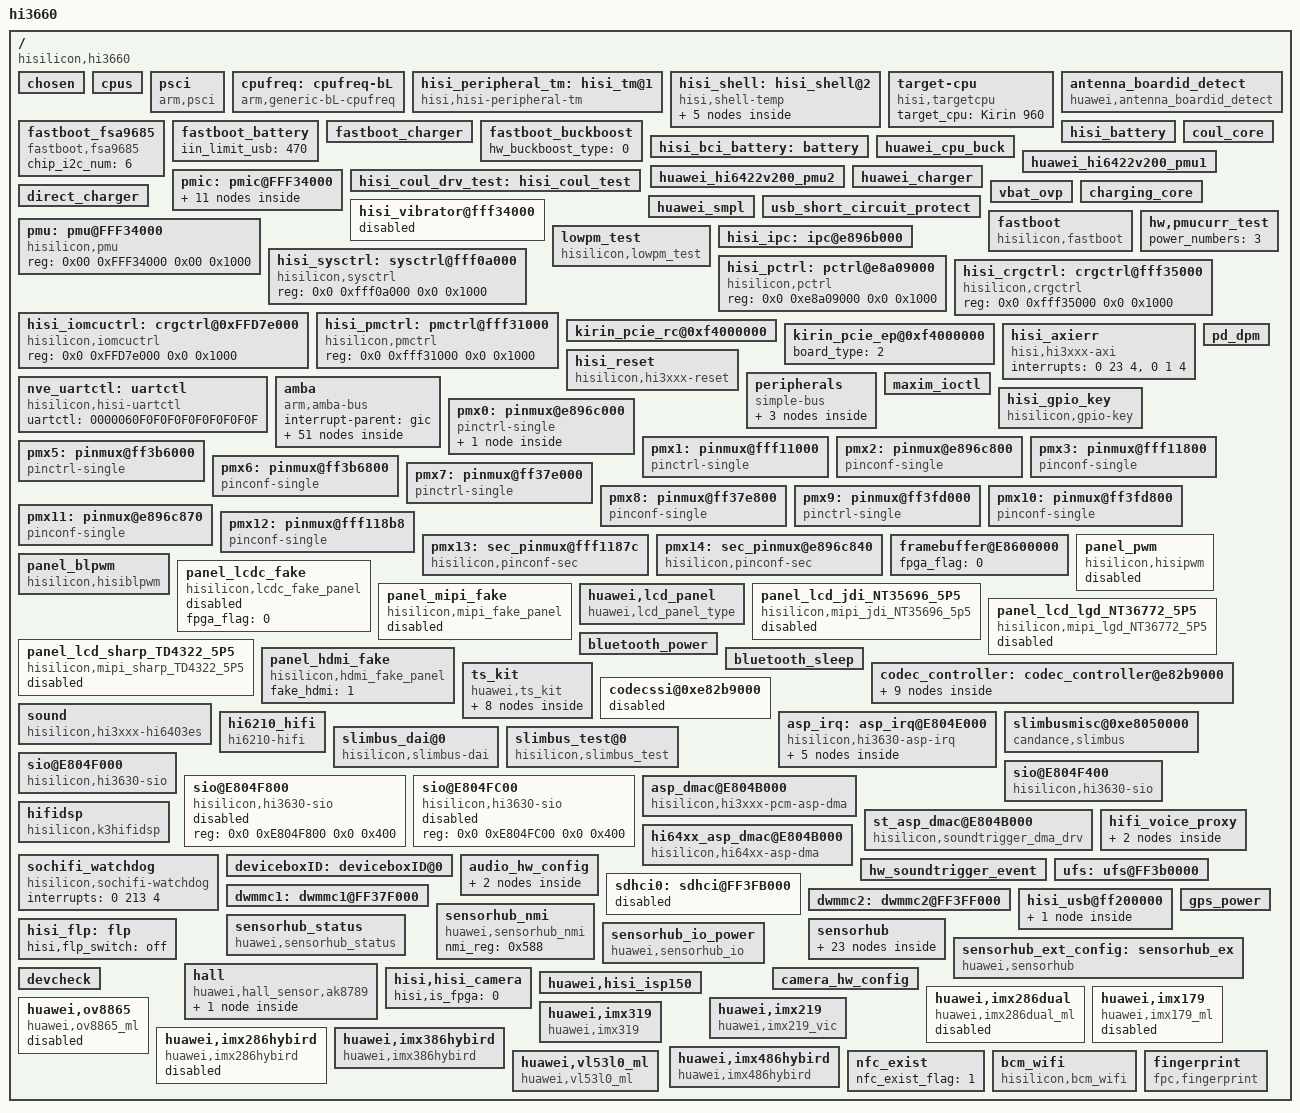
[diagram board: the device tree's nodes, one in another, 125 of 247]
/**
 * Copyright (C) 2014 Hisilicon Ltd.
 *
 *  This program is free software; you can redistribute it and/or modify
 *  it under the terms of the GNU General Public License version 2 as
 *  publishhed by the Free Software Foundation.
 */

/dts-v1/;
/include/ "fastboot.dtsi"
/include/ "VICTORIA_TUGL_V1_pin.dtsi"
/include/ "VICTORIA_TUGL_V1_modem_pin.dtsi"
/include/ "hisi_3660_cci.dtsi"
/include/ "hisi_3660_gic.dtsi"
/include/ "hisi_3660_timer.dtsi"
/include/ "hisi_3660.dtsi"
/include/ "hisi_3660_i2c.dtsi"
/include/ "hisi_64xx_codec.dtsi"
/include/ "VICTORIA_TUGL_V1_hi6402_pin.dtsi"
/include/ "VICTORIA_TUGL_V1_sec_pin.dtsi"
/include/ "hisi_bci_battery.dtsi"
/include/ "hisi_battery.dtsi"
/include/ "desayatl_3100_39k_4400_25.dtsi"
/include/ "scudlgc_3100_200k_4400_25.dtsi"
/include/ "sunwodasony_3100_110k_4400_40.dtsi"
/include/ "usb_short_circuit_protect.dtsi"
/include/ "huawei_charger.dtsi"
/include/ "hisi_coul.dtsi"
/include/ "fastboot_battery.dtsi"
/include/ "fastboot_charger.dtsi"
/include/ "fastboot_buckboost.dtsi"
/include/ "huawei_pmucurr_test.dtsi"
/include/ "huawei_smpl.dtsi"
/include/ "hisi_3660_thermal.dtsi"
/include/ "hisi_power_ip_test.dtsi"
/include/ "huawei_devdetect.dtsi"
/include/ "hisi_3660_cpu.dtsi"
/include/ "huawei_usbswitch.dtsi"
/include/ "huawei_usbpd.dtsi"
/include/ "huawei_gps.dtsi"
/include/ "hisi_3660_framebuffer.dtsi"
/include/ "modem/hisi_modem_balong.dtsi"
/include/ "hisi_6421v500_pmic_led.dtsi"
/include/ "hisi_rtc.dtsi"
/include/ "hisi_3660_vibrator.dtsi"
/include/ "huawei_voltage_detection.dtsi"
/include/ "hisi_3660_vowifi_proxy.dtsi"
/include/ "hisi_soundtrigger_event.dtsi"
/include/ "huawei_audio.dtsi"
/include/ "huawei_smartpa.dtsi"
/include/ "huawei_anc_hs.dtsi"

/include/ "huawei_bluetooth.dtsi"
/include/ "huawei_connectivity.dtsi"
/include/ "huawei_hall_inputhub.dtsi"
/include/ "hisi_sim_hotplug.dtsi"
/include/ "huawei_buckboost.dtsi"
/include/ "huawei_bastet.dtsi"
/include/ "huawei_cpu_buck.dtsi"
/include/ "lcdkit/default/devkit_lcd.dtsi"
/include/ "lcdkit/victoria_va/devkit_lcd.dtsi"

/ {
	#address-cells = <2>;
	#size-cells = <2>;
	model = "hi3660";
	compatible = "hisilicon,hi3660";
	interrupt-parent = <&gic>;
	hisi,boardid = <5 5 8 0>;
	hisi,boardname = "VICTORIA_TUGL_V1";
	hisi,modem_id = <0x3A020000>;

	hisi,sub_platform_info3 = "Kirin960";
	hisi,provider3 = "BALONG";
	hisi,sub_platform_info2 = "Kirin960";
	hisi,provider2 = "BALONG";
	hisi,sub_platform_info1 = "Kirin960";
	hisi,provider1 = "BALONG";
	hisi,sub_platform_info0 = "Kirin960";
	hisi,provider0 = "HUAWEI_K3";

	hisi,platform_num = <4>;

	chosen{};

	cpus {
		status = "ok";
	};

        psci {
                compatible      = "arm,psci";
                method          = "smc";
                cpu_suspend     = <0xc4000001>;
                cpu_off         = <0x84000002>;
                cpu_on          = <0xc4000003>;
                system_off      = <0x84000008>;
                system_reset    = <0x84000009>;
        };

	/* cpufreq  device */
	cpufreq: cpufreq-bL {
		compatible = "arm,generic-bL-cpufreq";
		status = "ok";
	};

	hisi_peripheral_tm: hisi_tm@1 {
		compatible = "hisi,hisi-peripheral-tm";
		hisi,peripheral_sensors = <8>;

		hisi,detect_system_h_tm_chanel = <12>;
		hisi,detect_system_h_tm_ntc = "austin_hkadc_soc_temp_table";
		hisi,detect_system_h_tm_state = "enable";

		hisi,detect_flash_led_tm_chanel = <5>;
		hisi,detect_flash_led_tm_ntc = "austin_hkadc_soc_temp_table";
		hisi,detect_flash_led_tm_state = "enable";

		hisi,detect_charger_tm_chanel = <13>;
		hisi,detect_charger_tm_ntc = "austin_hkadc_soc_temp_table";
		hisi,detect_charger_tm_state = "enable";

		hisi,detect_pa_0_tm_chanel = <11>;
		hisi,detect_pa_0_tm_ntc = "austin_hkadc_pa_temp_table";
		hisi,detect_pa_0_tm_state = "enable";

		hisi,detect_pa_1_tm_chanel = <13>;
		hisi,detect_pa_1_tm_ntc = "austin_hkadc_pa_temp_table";
		hisi,detect_pa_1_tm_state = "disable";

		hisi,detect_dcxo0_tm_chanel = <3>;
		hisi,detect_dcxo0_tm_ntc = "austin_hkadc_adc_temp_table";
		hisi,detect_dcxo0_tm_state = "enable";

		hisi,detect_shell_tm_chanel = <7>;
		hisi,detect_shell_tm_ntc = "austin_hkadc_soc_temp_table";
		hisi,detect_shell_tm_state = "disable";

		hisi,detect_charger1_tm_chanel = <4>;
		hisi,detect_charger1_tm_ntc = "austin_hkadc_soc_temp_table";
		hisi,detect_charger1_tm_state = "disable";
	};
    hisi_shell: hisi_shell@2 {
        compatible = "hisi,shell-temp";
        interval = <5000>;
        bias = <94520>;
        count = <6>;
        status = "ok";
        sensors {
            sensor0 {
                type = "system_h";
                coef = "4797","24314","23728","19377","16468","6529";
            };
            sensor1 {
                type = "charger";
                coef = "0","2829","5059","4054","3680","5025";
            };
            sensor2 {
                type = "pa_0";
                coef = "22826","14544","9325","8292","8056","14017";
            };
            sensor3 {
                type = "dcxo0";
                coef = "0","-24143","-18706","-19780","-19364","-19867";
            };
        };
    };

	target-cpu {
		compatible = "hisi,targetcpu";
		target_cpu = "Kirin 960";
	};
	antenna_boardid_detect:antenna_boardid_detect{
		compatible = "huawei,antenna_boardid_detect";
		gpio1 = <&gpio5 3 0>;
		temp_gpio = "gpio1";
		expect_value = <1>;
		pinctrl-names = "default", "idle";
		pinctrl-0 = <&gpio043_cfg_func &gpio043_pmx_func>;
		pinctrl-1 = <&gpio043_cfg_idle &gpio043_pmx_idle>;
		status = "ok";
	};
	fastboot_fsa9685: fastboot_fsa9685{
		compatible = "fastboot,fsa9685";
		chip_i2c_num = <6>;
		status = "ok";
	};
	fastboot_battery:fastboot_battery {
		iin_limit_usb = <470>;
		status = "ok";
	};
	fastboot_charger:fastboot_charger {
		hw_charger_type = <4>;
		chip_i2c_num = <6>;
		status = "ok";
	};
	fastboot_buckboost: fastboot_buckboost{
		hw_buckboost_type = <0>;
		status = "ok";
	};
	hisi_battery:hisi_battery {
		status = "ok";
		batt_name = <&desayatl_3100_39k_4400_25 &scudlgc_3100_200k_4400_25 &sunwodasony_3100_110k_4400_40>;
	};
	hisi_bci_battery:battery {
		battery_design_fcc = <3200>;
		battery_board_type = <2>; /*0:sft 1:udp 2:asic*/
		status = "ok";
	};
	coul_core:coul_core {
		adc_batt_id = <6>;
		adc_batt_temp = <10>;
		r_coul_mohm = <5>;
		last_soc_enable = <1>;
		soc_at_term = <98>;
		 basp_policy = <
			3 50000 6  200 6
			2 40000 8  50  8
			1 30000 9  0   9
			0 0     10 0   10
			>;
		status = "ok";
	};
	huawei_cpu_buck: huawei_cpu_buck{
		status = "ok";
	};
	huawei_hi6422v200_pmu1: huawei_hi6422v200_pmu1 {
		status = "ok";
	};
	huawei_hi6422v200_pmu2: huawei_hi6422v200_pmu2 {
		status = "ok";
	};

	pmic:pmic@FFF34000{
		gpios = <&gpio27 6 0>;
		hisilicon,pmic_fpga_flag=<0>;
		pmic_led: pmic_led@a0 {
			status = "ok";
		};
		pmic_rtc: pmic_rtc@a0 {
			status = "ok";
		};
		ponkey:ponkey@b1{
			lcd_on_off_timeout = <10000>;
			status = "ok";
		};
		hi6421v500_coul: hi6421v500_coul@1 {
			status = "ok";
		};
		huawei_usbvbus {
			support_pd = <1>;
			status = "ok";
		};
        pmic_mntn: pmic_mntn@a0 {
            status = "ok";
            OCP@a3 {
                compatible = "hisilicon,pmic-mntn-ocp-reg0x126";
                hisilicon,inacceptable-event = <0x34>;
                hisilicon,event-bit-name = "ldo20","ldo19","ldo17","ldo16","ldo15","ldo14","ldo13","ldo12";
                hisilicon,event-ops-reg = <0x7E 0x7C 0x7A 0x78 0x76 0x74 0x72 0x70>;
            };
            OCP@a4 {
                compatible = "hisilicon,pmic-mntn-ocp-reg0x127";
                hisilicon,inacceptable-event = <0xF7>;
                hisilicon,event-bit-name = "ldo28","ldo27","ldo26","ldo25","ldo24","ldo23","ldo22","ldo21";
                hisilicon,event-ops-reg = <0x8E 0x8C 0x8A 0x88 0x86 0x84 0x82 0x80>;
            };
            OCP@a5 {
                compatible = "hisilicon,pmic-mntn-ocp-reg0x128";
                hisilicon,inacceptable-event = <0xC1>;
                hisilicon,event-bit-name = "classd","reserved","reserved","reserved","ldo32","ldo31","ldo30","ldo29";
                hisilicon,event-ops-reg = <0xA6 0xDEAD 0xDEAD 0xDEAD 0x96 0x94 0x92 0x90>;
            };

        };
	};
	hisi_coul_drv_test:hisi_coul_test {
		status = "ok";
	};
	huawei_charger: huawei_charger {
		pd_support = <1>;
		powerdown_charge_version = "2";
		support_usb_nonstandard_ico = <1>;
		support_standard_ico = <0>;
		ico_all_the_way = <0>;
		water_check_enabled = <1>;
		fcp_vindpm = <8100>;
		status = "ok";
	};
	vbat_ovp: vbat_ovp {
		status = "ok";
	};
	charging_core: charging_core{
		status = "ok";
		iterm = <124>;
		iin_usb = <470>;
		ichg_usb = <500>;
		ichg_fcp = <3200>;
		iin_fcp = <2000>;
		ichg_ac = <2100>;
		iin_ac = <2000>;
		inductance_para =
			"-32767", "15", "1900", "0",
			"15", "32767", "1900", "0";
	};
	direct_charger: direct_charger{
		use_5A = <1>;
		max_dc_bat_vol = <4350>;
		min_dc_bat_vol = <3500>;
		volt_para =
			"4000", "4150", "3250",
			"4200", "3250", "2250",
			"4380", "2250", "1000";
		compensate_r = <30>;
		cc_cable_detect_enable = <1>;
		ovp_en = <&gpio4 1 0>;
		scp_power_en = <&gpio2 4 0>;
		full_path_res_max = <140>;
		standard_cable_full_path_res_max = <200>;
		temp_para =
			"-32767", "10", "0",
			"10", "45", "4150",
			"45", "32767", "0";
		basp_policy = <
			3	200	6
			2	40	8
			1	20	9
			0	0	10 >;
		status = "ok";
	};
	huawei_smpl: huawei_smpl{
		status = "ok";
	};
	usb_short_circuit_protect: usb_short_circuit_protect{
		status = "ok";
	};

	hisi_vibrator@fff34000 {
		status = "disable";
	};

	fastboot {
		compatible = "hisilicon,fastboot";
		i2c3-pin = <0>;
		gpio-keyup = <205>;
		gpio-keydown = <202>;
		/*EMU_TYPE 0,FPGA 1,UDP 2,PRODUCT 3*/
		uart-board-type = <3>;
		/*UDP_TYPE 0,PRODUCT 1,FPGA 2,EMU 3*/
		lpm3-board-type = <1>;
		jtagtosd-board-type = <1>;
		motor-vib_type = <1>;
		motor-gpio_en = <147>;

		i2c-select = <1>;
		i2c-sel0-gpio = <44>;
		i2c-sel1-gpio = <45>;
		i2c-sel0-val = <0>;
		i2c-sel1-val = <0>;
	};

	pmu: pmu@FFF34000 {
		compatible = "hisilicon,pmu";
		reg = <0x00 0xFFF34000 0x00 0x1000>;
		status = "ok";
	};
	hw,pmucurr_test{
		power_numbers = <3>;
		status = "ok";
	};
	lowpm_test {
		compatible = "hisilicon,lowpm_test";
		sr_plat_flag = <1>;
		reg = <0x0 0xfff32000 0x0 0x1000>;
		status = "ok";
	};
	hisi_ipc: ipc@e896b000 {
		status = "ok";
	};

        hisi_sysctrl: sysctrl@fff0a000 {
                compatible = "hisilicon,sysctrl";
                reg = <0x0 0xfff0a000 0x0 0x1000>;
                status = "ok";
        };

        hisi_pctrl: pctrl@e8a09000 {
                compatible = "hisilicon,pctrl";
                reg = <0x0 0xe8a09000 0x0 0x1000>;
                status = "ok";
        };

        hisi_crgctrl: crgctrl@fff35000 {
                compatible = "hisilicon,crgctrl";
                reg = <0x0 0xfff35000 0x0 0x1000>;
                status = "ok";
        };

	hisi_iomcuctrl: crgctrl@0xFFD7e000 {
                compatible = "hisilicon,iomcuctrl";
                reg = <0x0 0xFFD7e000 0x0 0x1000>;
                status = "ok";
        };

        hisi_pmctrl: pmctrl@fff31000 {
                compatible = "hisilicon,pmctrl";
                reg = <0x0 0xfff31000 0x0 0x1000>;
                status = "ok";
        };

	kirin_pcie_rc@0xf4000000 {
		board_type = <2>;
		wl_power = <150>;
		eye_param_ctrl2 = <0x1540AA4B>;
		eye_param_ctrl3 = <0x14003FFF>;

		/*EP Device Description: here describe BCM 4359*/
		ep_vend_id = <0x14e4>;
		ep_dev_id = <0x4355>;
		ep_ltr_latency = <0x10031003>;
		ep_l1ss_ctrl2 = <0x61>;
		l1ss_ctrl1 = <0x4004370F>;
		status = "ok";
	};

	kirin_pcie_ep@0xf4000000 {
		board_type = <2>;
	};

	hisi_axierr {
	        compatible = "hisi,hi3xxx-axi";
	        interrupts = <0 23 4>, <0 1 4>;
	        status = "ok";
        };

    hisi_reset {
            compatible = "hisilicon,hi3xxx-reset";
            status = "ok";
        };

	peripherals {
		compatible = "simple-bus";
		#address-cells = <1>;
		#size-cells = <1>;
		ranges = <0x0 0x00000000 0x0 0xffffffff>;

		clk6250khz: clk6250khz {
			compatible = "fixed-clock";
			#clock-cells = <0>;
			clock-frequency = <6297600>;
			clock-output-names = "clk6250khz";
		};
/*
		clk4800khz: clk4800khz {
			compatible = "fixed-clock";
			#clock-cells = <0>;
			clock-frequency = <32768>;
			clock-output-names = "clk4800khz";
		};
*/

		dma0: dma@fdf30000 {
			status = "ok";
		};

		iomcu_dma: dma@ffd77000 {
			status = "ok";
		};

	};
	nve_uartctl:uartctl {
		compatible = "hisilicon,hisi-uartctl";
		uartctl = "0000060F0F0F0F0F0F0F0F0F";
	};

	pd_dpm {
		status = "ok";
	};

	amba {
		#address-cells = <2>;
		#size-cells = <2>;
		compatible = "arm,amba-bus";
		interrupt-parent = <&gic>;
		ranges;

		/*rtc0: rtc@FFF04000 {
				compatible = "arm,rtc-pl031", "arm,primecell";
				reg = <0xfff04000 0x1000>;
				interrupts = <0 46 0x4>;
				clocks = <&pclk>;
				clock-names = "apb_pclk";
				status = "ok";
		};*/

		/*rtc1: rtc@FFF05000 {
				compatible = "arm,rtc-pl031", "arm,primecell";
				reg = <0xfff05000 0x1000>;
				interrupts = <0 47 0x4>;
				clocks = <&pclk>;
				clock-names = "apb_pclk";
				status = "ok";
		};*/

		watchdog0 {
			compatible = "arm,sp805", "arm,primecell";
			reg = <0x0 0xe8a06000 0x0 0x1000>;
			default-timeout = <24>;
			interrupts = <0 44 4>;
			clocks = <&pclk_gate_wd0 &pclk>;
			clock-names = "pclk_wd0", "apb_pclk";
			status = "ok";
		};

                iomcu_watchdog: watchdog@ffd7c000{
                        compatible = "hisilicon,iomcu-watchdog";
                        reg = <0x0 0xFFD7C000 0x0 0x1000>;
                        status = "ok";
                };

		/*wdt1@e8a07000 {
			compatible = "arm,sp805", "arm,primecell";
			reg = <0x0 0xe8a07000 0x0 0x1000>;
			interrupts = <0 45 4>;
			clocks = <&pclk_gate_wd0 &pclk>;
			clock-names = "pclk_wd0", "apb_pclk";
		};*/

		serial0: uart@fdf02000 {
			pinctrl-names = "default", "idle";
			pinctrl-0 = <&gpio053_pmx_func &gpio054_pmx_func &gpio053_cfg_func &gpio054_cfg_func>;
			pinctrl-1 = <&gpio053_pmx_idle &gpio054_pmx_idle &gpio053_cfg_idle &gpio054_cfg_idle>;
			dma-names = "", "";
			dmas = <>;
			clock-rate = <0 19200000>;
			status = "disabled";
		};

		serial1: uart@fdf00000 {
			pinctrl-names = "default", "idle";
			pinctrl-0 = <>;
			pinctrl-1 = <>;
			clock-rate = <0 160000000>;
			status = "disabled";
			reset-enable-flag = <1>;
		};

		serial2: uart@fdf03000 {
			pinctrl-names = "default", "idle";
			pinctrl-0 = <>;
			pinctrl-1 = <>;
			clock-rate = <0 160000000>;
			status = "ok";
			reset-enable-flag = <1>;
		};

		serial3: uart@ffd74000 {
			pinctrl-names = "default", "idle";
			pinctrl-0 = <&gpio057_pmx_func &gpio058_pmx_func &gpio059_pmx_func &gpio060_pmx_func &gpio057_cfg_func &gpio058_cfg_func &gpio059_cfg_func &gpio060_cfg_func>;
			pinctrl-1 = <&gpio057_pmx_idle &gpio058_pmx_idle &gpio059_pmx_idle &gpio060_pmx_idle &gpio057_cfg_idle &gpio058_cfg_idle &gpio059_cfg_idle &gpio060_cfg_idle>;
			dma-names = "", "";
			dmas = <>;
			clock-rate = <0 100000000>;
			status = "ok";
			reset-enable-flag = <0>;
		};

		serial4: uart@fdf01000 {
			pinctrl-names = "default", "idle";
			pinctrl-0 = <&gpio061_pmx_func &gpio062_pmx_func &gpio063_pmx_func &gpio064_pmx_func &gpio061_cfg_func &gpio062_cfg_func &gpio063_cfg_func &gpio064_cfg_func>;
			pinctrl-1 = <&gpio061_pmx_idle &gpio062_pmx_idle &gpio063_pmx_idle &gpio064_pmx_idle &gpio061_cfg_idle &gpio062_cfg_idle &gpio063_cfg_idle &gpio064_cfg_idle>;
			clock-rate = <0 160000000>;
			status = "ok";
			reset-enable-flag = <1>;
		};

		serial5: uart@fdf05000 {
			pinctrl-names = "default", "idle";
			pinctrl-0 = <>;
			pinctrl-1 = <>;
			clock-rate = <0 160000000>;
			status = "ok";
			reset-enable-flag = <1>;
		};

		serial6: uart@fff32000 {
			pinctrl-names = "default", "idle";
			pinctrl-0 = <&gpio055_pmx_func &gpio056_pmx_func &gpio055_cfg_func &gpio056_cfg_func>;
			pinctrl-1 = <&gpio055_pmx_idle &gpio056_pmx_idle &gpio055_cfg_idle &gpio056_cfg_idle>;
			clock-rate = <0 19200000>;
			console-fifo-enable = <1>;
			console-fifo-size = <262144>;/* 256k */
			console-fifo-cpuon = <3>;
			status = "ok";
			reset-enable-flag = <1>;
		};
		dx_cc63p: dx_cc63p@fdf0e000 {
			compatible = "dx,cc63p";
			reg = <0x0 0xfdf0e000 0x0 0x1000>;
			interrupt-parent = <&gic>;
			interrupts = <0 135 4>;
			status = "ok";
		};

		spi0: spi@ffd70000 {
			status = "ok";
			clock-rate = <0 32000000>;
			pinctrl-names = "default", "idle";
			pinctrl-0 = <&gpio044_pmx_func &gpio045_pmx_func &gpio044_cfg_func &gpio045_cfg_func>;
			pinctrl-1 = <&gpio044_pmx_idle &gpio045_pmx_idle &gpio044_cfg_idle &gpio045_cfg_idle>;
			spi_dev0: spi_dev0@0 {
					compatible = "spi_dev0";
					spi-max-frequency = <100000>;
					reg = <0>;
					pl022,com-mode = <0>;
					pl022,interface = <0>;
					pl022,rx-level-trig = <3>;
					pl022,tx-level-trig = <3>;
					pl022,ctrl-len = <7>;
					pl022,wait-state = <0>;
					pl022,duplex = <0>;
					pl022,slave-tx-disable = <0>;
			};

			spi_dev2: spi_dev2@2 {
					compatible = "spi_dev2";
					spi-max-frequency = <13000000>;
					reg = <2>;
					pl022,com-mode = <2>;
					pl022,interface = <0>;
					pl022,rx-level-trig = <3>;
					pl022,tx-level-trig = <3>;
					pl022,ctrl-len = <7>;
					pl022,wait-state = <0>;
					pl022,duplex = <0>;
					pl022,slave-tx-disable = <0>;
			};

			spi_dev3: spi_dev3@3 {
					compatible = "spi_dev3";
					spi-max-frequency = <13000000>;
					reg = <3>;
					pl022,com-mode = <0>;
					pl022,interface = <0>;
					pl022,rx-level-trig = <3>;
					pl022,tx-level-trig = <3>;
					pl022,ctrl-len = <7>;
					pl022,wait-state = <0>;
					pl022,duplex = <0>;
					pl022,slave-tx-disable = <0>;
			};
		};

		spi1: spi@fdf08000 {
			/* secure */
			status = "ok";
			clock-rate = <0 46000000>;
			pinctrl-names = "default", "idle";
			pinctrl-0 = <>;
			pinctrl-1 = <>;
			jdi_bu21150: jdi_bu21150@10 {
					compatible = "jdi,bu21150";
					spi-max-frequency = <20000000>;
					reg = <0>;
					pl022,com-mode = <0>;
					pl022,interface = <0>;
					pl022,rx-level-trig = <3>;
					pl022,tx-level-trig = <3>;
					pl022,ctrl-len = <7>;
					pl022,wait-state = <0>;
					pl022,duplex = <0>;
					pl022,slave-tx-disable = <0>;
					jdi_bu21150,irq_gpio = <212>;
					jdi_bu21150,cs_gpio = <18>;
					jdi_bu21150,rst_gpio = <65>;
					jdi_bu21150,vdd_dig-supply = <&ldo4>;
					jdi_bu21150,vdd_ana-supply = <&ldo17>;

			};
		};

		spi3: spi@ff3b3000 {
			status = "ok";
			clock-rate = <0 80000000>;
			pinctrl-names = "default", "idle";
			pinctrl-0 = <&gpio146_pmx_func &gpio147_pmx_func &gpio148_pmx_func &gpio146_cfg_func &gpio147_cfg_func
					&gpio148_cfg_func>;
			pinctrl-1 = <&gpio146_pmx_idle &gpio147_pmx_idle &gpio148_pmx_idle &gpio146_cfg_idle &gpio147_cfg_idle
					&gpio148_cfg_idle>;
			spi_dev30: spi_dev30@30 {
					compatible = "spi_dev30";
					spi-max-frequency = <100000>;
					reg = <0>;
					pl022,com-mode = <2>;
					pl022,interface = <0>;
					pl022,rx-level-trig = <3>;
					pl022,tx-level-trig = <3>;
					pl022,ctrl-len = <7>;
					pl022,wait-state = <0>;
					pl022,duplex = <0>;
					pl022,slave-tx-disable = <0>;
			};

			spi_dev31: spi_dev31@31 {
					compatible = "spi_dev31";
					spi-max-frequency = <13000000>;
					reg = <1>;
					pl022,com-mode = <1>;
					pl022,interface = <0>;
					pl022,rx-level-trig = <3>;
					pl022,tx-level-trig = <3>;
					pl022,ctrl-len = <7>;
					pl022,wait-state = <0>;
					pl022,duplex = <0>;
					pl022,slave-tx-disable = <0>;
			};

			spi_dev32: spi_dev32@32 {
					compatible = "spi_dev32";
					spi-max-frequency = <13000000>;
					reg = <2>;
					pl022,com-mode = <2>;
					pl022,interface = <0>;
					pl022,rx-level-trig = <3>;
					pl022,tx-level-trig = <3>;
					pl022,ctrl-len = <7>;
					pl022,wait-state = <0>;
					pl022,duplex = <0>;
					pl022,slave-tx-disable = <0>;
			};

			spi_dev33: spi_dev33@33 {
					compatible = "spi_dev33";
					spi-max-frequency = <13000000>;
					reg = <3>;
					pl022,com-mode = <0>;
					pl022,interface = <0>;
					pl022,rx-level-trig = <3>;
					pl022,tx-level-trig = <3>;
					pl022,ctrl-len = <7>;
					pl022,wait-state = <0>;
					pl022,duplex = <0>;
					pl022,slave-tx-disable = <0>;
			};
		};
		spi4: spi@fdf06000 {
			/* secure */
			status = "disabled";
			clock-rate = <0 46000000>;
			pinctrl-names = "default", "idle";
			pinctrl-0 = <>;
			pinctrl-1 = <>;
			spi_dev40: spi_dev40@40 {
					compatible = "spi_dev40";
					spi-max-frequency = <5000000>;
					reg = <0>;
					pl022,com-mode = <2>;
					pl022,interface = <0>;
					pl022,rx-level-trig = <3>;
					pl022,tx-level-trig = <3>;
					pl022,ctrl-len = <7>;
					pl022,wait-state = <0>;
					pl022,duplex = <0>;
					pl022,slave-tx-disable = <0>;
			};

			spi_dev41: spi_dev41@41 {
					compatible = "spi_dev41";
					spi-max-frequency = <13000000>;
					reg = <1>;
					pl022,com-mode = <1>;
					pl022,interface = <0>;
					pl022,rx-level-trig = <3>;
					pl022,tx-level-trig = <3>;
					pl022,ctrl-len = <7>;
					pl022,wait-state = <0>;
					pl022,duplex = <0>;
					pl022,slave-tx-disable = <0>;
			};

			spi_dev42: spi_dev42@42 {
					compatible = "spi_dev42";
					spi-max-frequency = <13000000>;
					reg = <2>;
					pl022,com-mode = <2>;
					pl022,interface = <0>;
					pl022,rx-level-trig = <3>;
					pl022,tx-level-trig = <3>;
					pl022,ctrl-len = <7>;
					pl022,wait-state = <0>;
					pl022,duplex = <0>;
					pl022,slave-tx-disable = <0>;
			};

			spi_dev43: spi_dev43@43 {
					compatible = "spi_dev43";
					spi-max-frequency = <13000000>;
					reg = <3>;
					pl022,com-mode = <0>;
					pl022,interface = <0>;
					pl022,rx-level-trig = <3>;
					pl022,tx-level-trig = <3>;
					pl022,ctrl-len = <7>;
					pl022,wait-state = <0>;
					pl022,duplex = <0>;
					pl022,slave-tx-disable = <0>;
			};
		};

		/* I2C0 ~ I2C */
		i2c0: i2c@FFD71000 {
			status = "disabled";
			clock-rate = <0 32000000>;
			pinctrl-names = "default", "idle";
			pinctrl-0 = <>;
			pinctrl-1 = <>;
			//cs-gpios = <>, <>;
		};

		i2c1: i2c@FFD72000 {
			status = "ok";
			clock-rate = <0 32000000>;
			pinctrl-names = "default", "idle";
			pinctrl-0 = <&gpio185_pmx_func &gpio186_pmx_func &gpio185_cfg_func &gpio186_cfg_func>;
			pinctrl-1 = <&gpio185_pmx_idle &gpio186_pmx_idle &gpio185_cfg_idle &gpio186_cfg_idle>;
			cs-gpios = <&gpio23 1 0>, <&gpio23 2 0>;

			fusb30x_i2c1@22 {
				status = "ok";
				fairchild,int_n = <&gpio27 3 0>;
			};
			rt1711_i2c1@4e {
				status = "ok";
				rt1711,irq_pin = <&gpio27 3 0>;
			};
			tusb422_i2c1@20 {
				status = "ok";
				ti,alert-gpio = <&gpio27 3 0>;
			};
			rt9748: rt9748@67 {
				compatible = "rt9748";
				loadswitch_en = <&gpio2 3 0>;
				reg = <0x67>;
				status = "ok";
			};
		};

		i2c2: i2c@FFD73000 {
			status = "disabled";
			clock-rate = <0 32000000>;
			pinctrl-names = "default", "idle";
			pinctrl-0 = <&gpio187_pmx_func &gpio188_pmx_func &gpio187_cfg_func &gpio188_cfg_func>;
			pinctrl-1 = <&gpio187_pmx_idle &gpio188_pmx_idle &gpio187_cfg_idle &gpio188_cfg_idle>;
			cs-gpios = <&gpio23 3 0>, <&gpio23 4 0>;
		};

		i2c3: i2c@FDF0C000 {
			status = "ok";
			clock-rate = <0 107000000>;
			pinctrl-names = "default", "idle";
			pinctrl-0 = <&gpio013_pmx_func &gpio014_pmx_func &gpio013_cfg_func &gpio014_cfg_func>;
			pinctrl-1 = <&gpio013_pmx_idle &gpio014_pmx_idle &gpio013_cfg_idle &gpio014_cfg_idle>;
			cs-gpios = <&gpio1 5 0>, <&gpio1 6 0>;

			fsa7830_1:fsa7830_1@43 {
				huawei,adc_channel = <4>;
				huawei,input_cfg = <0xff>;
				huawei,switch_cfg = <0x8d 0x98 0xab 0xbb 0xc8 0xdb 0xeb 0xfd>;
				status = "disable";
			};
			ti,lm36923{
				compatible = "ti,lm36923","ti,lm36923_i2c3";
				reg = <0x36>;
				support = <1>;
				lm36923-led-num = <2>;/* default 3 led */
				lm36923-boost-ctrl-1 = <0x7f>;/* inductor select bit4 set to 1, 10 mH */
				lm36923-ctrl-mode = <0>;
				lcd-bl-ic-name = "LM36923YFFR";
				lm36923-boost-ctrl-dbc = <0x74>; /*reg val for dbc test*/
				fake_panel_enable_reg = <3>;
				status = "ok";
			};

			hisi,ncp6925@50{
				compatible = "hisi,ncp6925";
				reg = <0x50>;
				hisi,pmic_name = "ncp6925";
				hisi,pmic_index = <0>;
				hisi,slave_address = <0x50>;
				hisi,pmic-pin = <88 999 999>;
				hisi,pmic-voltage = <0x0 0x1 0x2 0x3 0x4 0x5 0x6>;
				hisi,pmic_sensor_1v8 = <1>;
				status = "ok";
			};
			max77813: max77813@18 {
				compatible = "max77813";
				gpio_pok = <&gpio18 4 0>;
				reg = <0x18>;
				status = "ok";
			};
		};

		i2c4: i2c@FDF0D000 {
			status = "ok";
			clock-rate = <0 107000000>;
			pinctrl-names = "default", "idle";
			pinctrl-0 = <&gpio038_pmx_func &gpio039_pmx_func &gpio038_cfg_func &gpio039_cfg_func>;
			pinctrl-1 = <&gpio038_pmx_idle &gpio039_pmx_idle &gpio038_cfg_idle &gpio039_cfg_idle>;
			cs-gpios = <&gpio4 6 0>, <&gpio4 7 0>;
			ti-drv2605@5a{
				status = "ok";
				ti,max-timeout-ms = <10000>;
				ti,label = "vibrator";
				reg = <0x5a>;
				compatible = "ti,drv2605";
				gpio-enable = <&gpio18 3 0>;
				lra_rated_voltage = <0x36>;
				lra_overdriver_voltage = <0x76>;
				lra_rtp_strength = <0x7F>;
			};

			huawei,lm3646@67{
				huawei,need-wakelock = <1>;
				huawei,flash-pin = <49 999 999>;
				status = "ok";
			};
			huawei,mp3336@27{
				huawei,need-wakelock = <1>;
				huawei,flash-pin = <49 999 999>;
				status = "ok";
			};

			pn547_nfc: nfc@28{
				status = "ok";
				nfc_on_type = "hisi_pmic";
				nfc_brcm_conf_name = "libnfc_brcm_victoria.conf";
				nfc_nxp_name = "libnfc_nxp_victoria.conf";
				nfc_card_num = <0x2>;
				clk_status ="pmu";
				pn547,dload = <&gpio6 0 0>;
				pn547,irq = <&gpio24 3 0>;
				pn547,ven = <>;
				pinctrl-1 = <&gpio048_pmx_idle &gpio195_pmx_idle>;
				pinctrl-0 = <&gpio048_pmx_func &gpio195_pmx_func>;
				pinctrl-names = "default","idle";
				clock-names = "clk_out0";
				clocks = <&clk_gate_out0>;
				reg = <0x28>;
				compatible = "hisilicon,pn547_nfc";
				nfc_chip_type = "pn551";
				nfc_single_channel = "true";
				nfc_ese_type = "hisee";
			};

			anc_max14744: anc_max14744@15{
				anc_hs_btn_hook_min_voltage = <155>;
				anc_hs_btn_hook_max_voltage = <196>;
				anc_hs_btn_volume_up_min_voltage = <200>;
				anc_hs_btn_volume_up_max_voltage = <245>;
				anc_hs_btn_volume_down_min_voltage = <250>;
				anc_hs_btn_volume_down_max_voltage = <308>;
				pinctrl-0 = <&gpio194_pmx_func &gpio011_pmx_func &gpio194_cfg_func &gpio011_cfg_func>;
				pinctrl-1 = <&gpio194_pmx_idle &gpio011_pmx_idle &gpio194_cfg_idle &gpio011_cfg_idle>;
				gpio_int = <&gpio24 2 0>;
				gpio_pwr_en = <&gpio1 3 0>;
				cam_ldo_used = <1>;
				cam_ldo_num = <2>;
				cam_ldo_value = <3300000>;
				chip_powered_on_time = <4>;/* it include PMIC powered_on time(2.73ms) + chip powered_on time(1ms) */
				status = "ok";
			};

			anc_ncx8293: anc_ncx8293@16{
				anc_hs_btn_hook_min_voltage = <155>;
				anc_hs_btn_hook_max_voltage = <196>;
				anc_hs_btn_volume_up_min_voltage = <200>;
				anc_hs_btn_volume_up_max_voltage = <245>;
				anc_hs_btn_volume_down_min_voltage = <250>;
				anc_hs_btn_volume_down_max_voltage = <308>;
				pinctrl-0 = <&gpio194_pmx_func &gpio011_pmx_func &gpio194_cfg_func &gpio011_cfg_func>;
				pinctrl-1 = <&gpio194_pmx_idle &gpio011_pmx_idle &gpio194_cfg_idle &gpio011_cfg_idle>;
				gpio_int = <&gpio24 2 0>;
				gpio_pwr_en = <&gpio1 3 0>;
				cam_ldo_used = <1>;
				cam_ldo_num = <2>;
				cam_ldo_value = <3300000>;
				chip_powered_on_time = <4>; /* it include PMIC powered_on time(2.73ms) + chip powered_on time(5ms), but anc_max14744 has delay 4ms before. */
				status = "ok";
			};

			max98925_smartpa_l:smartpa@31 {
				status = "ok";
				gain_incall = <0x16>;
				gain = <0x16>;
				iv_slot_change = <1>;
			};

			tps65132_phy: tps65132@3e{
				status = "ok";
				gpios = <&gpio15 5 0>, <&gpio4 5 0>; /*vsp vsn*/
				reg = <0x3e>;
				voltage_config = <1>; /*0:5.5v 1:5.8v 2:5.6v */
				compatible = "hisilicon,tps65132_phy";
			};
		};

		i2c6: i2c@FFD6A000 {
			status = "ok";
			clock-rate = <0 32000000>;
			pinctrl-names = "default", "idle";
			pinctrl-0 = <&gpio197_pmx_func &gpio196_pmx_func &gpio197_cfg_func &gpio196_cfg_func>;
			pinctrl-1 = <&gpio197_pmx_idle &gpio196_pmx_idle &gpio197_cfg_idle &gpio196_cfg_idle>;
			cs-gpios = <&gpio24 5 0>, <&gpio24 4 0>;

			hi6523_charger_i2c6: hi6523_charger_i2c6@6B{
				status = "ok";
				fcp_support = <0>;
				vclamp = <150>;
				bat_comp = <30>;
				ico_current_mode = <0>;
			};

			fairchild_fsa9685_i2c6: fsa9685_i2c6@25{
				usbid-enable = <0>;
				scp_support = <1>;
				status = "ok";
			};
		};

		i2c7: i2c@FDF0B000 {
			status = "ok";
			clock-rate = <0 107000000>;
			pinctrl-names = "default", "idle";
			pinctrl-0 = <&gpio187_pmx_func &gpio188_pmx_func &gpio187_cfg_func &gpio188_cfg_func>;
			pinctrl-1 = <&gpio187_pmx_idle &gpio188_pmx_idle &gpio187_cfg_idle &gpio188_cfg_idle>;
			cs-gpios = <&gpio23 3 0>, <&gpio23 4 0>;
		};
	};
	/* end amba */

	maxim_ioctl {
		status = "ok";
	};

	hisi_gpio_key {
		compatible = "hisilicon,gpio-key";
		pinctrl-names = "default", "idle";
		pinctrl-0 = <&gpio205_cfg_func &gpio202_cfg_func>;
		pinctrl-1 = <&gpio205_cfg_idle &gpio202_cfg_idle>;
		gpio-keyup,gpio-irq = <&gpio25 5 0>;
		gpio-keydown,gpio-irq = <&gpio25 2 0>;
		status = "ok";
	};

	pmx0: pinmux@e896c000 {
		compatible = "pinctrl-single", "pinctrl-single0";
		reg = <0x0 0xe896c000 0x0 0x1f0>;
		#gpio-range-cells = <3>;
		//ranges;
		pinctrl-single,register-width = <32>;
		pinctrl-single,function-mask = <7>;
		/* pin base, nr pins & gpio function */
		pinctrl-single,gpio-range = <&range 0 13 0 &range 25 95  0>;
		range: gpio-range {
			#pinctrl-single,gpio-range-cells = <3>;
		};
	};

	pmx1: pinmux@fff11000 {
		compatible = "pinctrl-single", "pinctrl-single1";
		reg = <0x0 0xfff11000 0x0 0x0a8>;
		#gpio-range-cells = <3>;
		//ranges;
		pinctrl-single,register-width = <32>;
		pinctrl-single,function-mask = <7>;
		/* pin base, nr pins & gpio function */
		pinctrl-single,gpio-range = <&range 0 27 0>;
	};

	pmx2: pinmux@e896c800 {
		compatible = "pinconf-single", "pinctrl-single2";
		reg = <0x0 0xe896c800 0x0 0x40>;
		//ranges;
		pinctrl-single,register-width = <32>;
	};

	pmx3: pinmux@fff11800 {
		compatible = "pinconf-single", "pinctrl-single3";
		reg = <0x0 0xfff11800 0x0 0x07c>;
		//ranges;
		pinctrl-single,register-width = <32>;
	};

	pmx5:pinmux@ff3b6000 {
		compatible = "pinctrl-single", "pinctrl-single5";
		reg = <0x0 0xff3b6000 0x0 0x030>;
		pinctrl-single,register-width = <32>;
		pinctrl-single,function-mask = <7>;
		pinctrl-single,gpio-range = <&range 0 12 0>;
	};

	pmx6:pinmux@ff3b6800 {
		compatible = "pinconf-single", "pinctrl-single6";
		reg = <0x0 0xff3b6800 0x0 0x030>;
		pinctrl-single,register-width = <32>;
	};

	pmx7:pinmux@ff37e000 {
		compatible = "pinctrl-single", "pinctrl-single7";
		reg = <0x0 0xff37e000 0x0 0x018>;
		pinctrl-single,register-width = <32>;
		pinctrl-single,function-mask = <7>;
		pinctrl-single,gpio-range = <&range 0 6 0>;
	};

	pmx8:pinmux@ff37e800 {
		compatible = "pinconf-single", "pinctrl-single8";
		reg = <0x0 0xff37e800 0x0 0x018>;
		pinctrl-single,register-width = <32>;
	};

	pmx9:pinmux@ff3fd000 {
		compatible = "pinctrl-single", "pinctrl-single9";
		reg = <0x0 0xff3fd000 0x0 0x018>;
		pinctrl-single,register-width = <32>;
		pinctrl-single,function-mask = <7>;
		pinctrl-single,gpio-range = <&range 0 6 0>;
	};

	pmx10:pinmux@ff3fd800 {
		compatible = "pinconf-single", "pinctrl-single10";
		reg = <0x0 0xff3fd800 0x0 0x018>;
		pinctrl-single,register-width = <32>;
	};

	pmx11: pinmux@e896c870 {
		compatible = "pinconf-single", "pinctrl-singlei2";
		reg = <0x0 0xe896c870 0x0 0x190>;
		//ranges;
		pinctrl-single,register-width = <32>;
	};

	pmx12: pinmux@fff118b8 {
		compatible = "pinconf-single", "pinctrl-singlei2";
		reg = <0x0 0xfff118b8 0x0 0x0>;
		//ranges;
		pinctrl-single,register-width = <32>;
	};


	pmx13:sec_pinmux@fff1187c {
		compatible = "hisilicon,pinconf-sec";
		reg = <0x0 0xfff1187c 0x0 0x3c>;
		pinctrl-single,register-width = <32>;
	};

	pmx14:sec_pinmux@e896c840 {
		compatible = "hisilicon,pinconf-sec";
		reg = <0x0 0xe896c840 0x0 0x2C>;
		pinctrl-single,register-width = <32>;
	};

	/* display start */
	framebuffer@E8600000 {
		fpga_flag = <0>;
	};

	panel_pwm {
		#address-cells = <2>;
		#size-cells = <2>;
		compatible = "hisilicon,hisipwm";
		reg = <0 0xE8A04000 0 0x1000>;
		clocks = <&clk_gate_pwm>;
		clock-names = "clk_pwm";
		//pinctrl-names = "default","idle";
		//pinctrl-0 = <&gpio182_pmx_func &gpio182_cfg_func>;
		//pinctrl-1 = <&gpio182_pmx_idle &gpio182_cfg_idle>;
		fpga_flag = <0>;
		status = "disabled";
	};

	panel_blpwm {
		#address-cells = <2>;
		#size-cells = <2>;
		compatible = "hisilicon,hisiblpwm";
		reg = <0 0xFFD75000 0 0x1000>;
		clocks = <&clk_gate_blpwm>;
		clock-names = "clk_blpwm";
		pinctrl-names = "default","idle";
		pinctrl-0 = <&gpio181_pmx_func &gpio182_pmx_func &gpio181_cfg_func &gpio182_cfg_func>;
		pinctrl-1 = <&gpio181_pmx_idle &gpio182_pmx_idle &gpio181_cfg_idle &gpio182_cfg_idle>;
		fpga_flag = <0>;
		status = "ok";
	};

	panel_lcdc_fake {
		#address-cells = <2>;
		#size-cells = <2>;
		compatible = "hisilicon,lcdc_fake_panel";
		fpga_flag = <0>;
		status = "disabled";
	};

	panel_mipi_fake {
		#address-cells = <2>;
		#size-cells = <2>;
		compatible = "hisilicon,mipi_fake_panel";
		gpios = <&gpio4 5 0>, <&gpio6 3 0>, <&gpio15 5 0>; /* vsn, bl_enable, vsp*/
		gpio_nums = <37 51 125>;
		fpga_flag = <0>;
		lcd-bl-ic-name = "LM36923YFFR";
		bl_enable_flag = <0>;
		status = "disabled";
	};

	huawei,lcd_panel {
		compatible = "huawei,lcd_panel_type";
		product_id = <1000>;
		detect_type = <2>; /*0:DETECT_GPIOID  1:DETECT_CHIPID  2:DETECT_LCD_TYPE */
		gpio_id = <46 50>; /*ID0 ID1*/
		gpio_cfg_addr = <0xE896C8BC 0xE896C8CC>; /*IOCG*/
		support_lcd_type = "LCDKIT";
		iovcc_ctrl_mode = <2>;
		iovcc_ctrl_gpio = <67>;
		bl_bus_id = <3>; /*lm36923 bus id*/
		lcd-bl-ic-name = "LM36923YFFR";
		lcd_panel_type = "auo_otm1901a_5p2_1080p_video";
	};
	panel_lcd_jdi_NT35696_5P5 {
		compatible = "hisilicon,mipi_jdi_NT35696_5p5";
		lcd-bl-type = <4>;
		lcd-bl-ic-name = "LM36923YFFR";
		lcd-display-type = <16>;
		gpios = <&gpio4 5 0>, <&gpio6 3 0>,  <&gpio15 5 0>, <&gpio5 0 0>, <&gpio5 6 0>, <&gpio6 2 0>, <&gpio8 3 0>;/*vsn bl_en vsp reset id0 id1 vddio_en*/
		gpio_nums = <37 51 125 40 23 46 65 50 67>; /*vsn bl vsp lcd_rst te id0 tp_rst id1 vddio_en*/
		lcdanalog-vcc-supply = <&ldo17>;
		pinctrl-names = "default", "idle";
		pinctrl-0 = <&gpio037_pmx_func &gpio125_pmx_func &gpio040_pmx_func &gpio046_pmx_func &gpio050_pmx_func &gpio037_cfg_func &gpio125_cfg_func &gpio040_cfg_func &gpio046_cfg_func &gpio050_cfg_func>;
		pinctrl-1 = <&gpio037_pmx_idle &gpio125_pmx_idle &gpio040_pmx_idle &gpio046_pmx_idle &gpio050_pmx_idle &gpio037_cfg_idle &gpio125_cfg_idle &gpio040_cfg_idle &gpio046_cfg_idle &gpio050_cfg_idle>;
		status = "disabled";
	};
	panel_lcd_lgd_NT36772_5P5 {
		compatible = "hisilicon,mipi_lgd_NT36772_5P5";
		lcd-bl-type = <4>;
		lcd-bl-ic-name = "LM36923YFFR";
		lcd-display-type = <16>;
		gpios = <&gpio4 5 0>, <&gpio6 3 0>,  <&gpio15 5 0>, <&gpio5 0 0>, <&gpio5 6 0>, <&gpio6 2 0>, <&gpio8 3 0>;/*vsn bl_en vsp reset id0 id1 vddio_en*/
		gpio_nums = <37 51 125 40 23 46 65 50 67>; /*vsn bl vsp lcd_rst te id0 tp_rst id1 vddio_en*/
		pinctrl-names = "default", "idle";
		pinctrl-0 = <&gpio037_pmx_func &gpio125_pmx_func &gpio040_pmx_func &gpio046_pmx_func &gpio050_pmx_func &gpio037_cfg_func &gpio125_cfg_func &gpio040_cfg_func &gpio046_cfg_func &gpio050_cfg_func>;
		pinctrl-1 = <&gpio037_pmx_idle &gpio125_pmx_idle &gpio040_pmx_idle &gpio046_pmx_idle &gpio050_pmx_idle &gpio037_cfg_idle &gpio125_cfg_idle &gpio040_cfg_idle &gpio046_cfg_idle &gpio050_cfg_idle>;
		status = "disabled";
	};

	panel_lcd_sharp_TD4322_5P5 {
		compatible = "hisilicon,mipi_sharp_TD4322_5P5";
		lcd-bl-type = <4>;
		lcd-bl-ic-name = "LM36923YFFR";
		gpios = <&gpio4 5 0>, <&gpio6 3 0>,  <&gpio15 5 0>, <&gpio5 0 0>, <&gpio5 6 0>, <&gpio6 2 0>, <&gpio8 3 0>; /*vsn bl_en vsp reset id0 id1 vddio_en*/
		gpio_nums = <37 51 125 40 23 46 65 50 67>; /*vsn bl vsp lcd_rst te id0 tp_rst id1 vddio_en*/
		lcdanalog-vcc-supply = <&ldo17>;
		pinctrl-names = "default", "idle";
		pinctrl-0 = <&gpio037_pmx_func &gpio125_pmx_func &gpio040_pmx_func &gpio046_pmx_func &gpio050_pmx_func &gpio037_cfg_func &gpio125_cfg_func &gpio040_cfg_func &gpio046_cfg_func &gpio050_cfg_func>;
		pinctrl-1 = <&gpio037_pmx_idle &gpio125_pmx_idle &gpio040_pmx_idle &gpio046_pmx_idle &gpio050_pmx_idle &gpio037_cfg_idle &gpio125_cfg_idle &gpio040_cfg_idle &gpio046_cfg_idle &gpio050_cfg_idle>;
		support-dynamic-gamma = <1>;
		status = "disabled";
	};
	/* display end */

	panel_hdmi_fake {
		#address-cells = <2>;
		#size-cells = <2>;
		compatible = "hisilicon,hdmi_fake_panel";
		fake_hdmi = <1>;
		status = "ok";
	};

        bluetooth_power: bluetooth_power{
                status = "ok";
                huawei,bt_en = <126>;
                huawei,no_vio_switch = <1>;
        };

        bluetooth_sleep: bluetooth_sleep{
                status = "ok";
                huawei,host_wake_bt = <44>;
                huawei,bt_wake_host = <192>;
        };

    /*ts kit*/
	ts_kit {
		compatible = "huawei,ts_kit";
		bus_type = "i2c";
		product = "victoria";
		bus_id = <7>;
		has_virtualkey = <0>;
		fpga_flag = <0>;
		irq_gpio = <&gpio26 4 0>;
		reset_gpio = <&gpio8 1 0>;
		aft_enable = <1>;
		drv_stop_width = <10>;
		lcd_width = <1080>;
		lcd_height = <1920>;
		synaptics: touchscreen@70 {
			compatible = "synaptics";
			algo_id = <1>;
			raw_data_limit = "5000",
					"0",
					"5000",
					"-5000",
					"5000",
					"-5000",
					"5000",
					"-5000";
			rawdata_get_timeout = <10>;
			y_max_mt = <1920>;
			x_max_mt = <1080>;
			y_max = <1920>;
			x_max = <1080>;
			irq_config = <0>;
			synaptics-io-supply = <&ldo4>;
			synaptics-vdd-supply = <&ldo17>;
			pinctrl-1 = <&gpio065_cfg_idle>;
			pinctrl-0 = <&gpio065_cfg_func>;
			pinctrl-names = "default", "idle";
			vddio_regulator_type = <0>;
			vddio_gpio_type = <1>;
			vddio_ctrl_gpio = <&gpio8 3 0>;
			vci_regulator_type = <1>;
			vci_gpio_type = <0>;
			ic_type = <4>;
			projectid_len = <10>;
			vci_value = <3300000>;
			unite_cap_test_interface =<1>;
			report_rate_test =<0>;
			delay_for_fw_update = <1>;
			ghost_detect_support = <1>;
			need_wd_check_status = <1>;
			check_status_watchdog_timeout = <5000>;
			use_new_oem_structure = <1>;
			/* for avert misoper algo */
			feature_all = <1>;
			feature_resend_point = <1>;
			feature_orit_support = <1>;
			feature_reback_bt = <1>;
			lcd_width = <1080>;
			lcd_height = <1920>;
			click_time_limit = <180>;
			click_time_bt = <200>;
			edge_position = <30>;
			edge_postion_secondline = <50>;
			bt_edge_x = <80>;
			bt_edge_y = <700>;
			move_limit_x = <36>;
			move_limit_y = <36>;
			move_limit_x_t = <36>;
			move_limit_y_t = <36>;
			move_limit_x_bt = <60>;
			move_limit_y_bt = <60>;
			edge_y_confirm_t = <24>;
			edge_y_dubious_t = <16>;
			edge_y_avg_bt = <3>;
			edge_xy_down_bt = <8>;
			edge_xy_confirm_t = <36>;
			max_points_bak_num = <15>;
			/* for avert misoper algo in driver */
			drv_stop_width = <10>;
			sensor_x_width = <4>;
			sensor_y_width = <4>;
			is_multi_protocal = <1>;

			VCTO24080 {
				producer = "jdi";
				roi_data_addr = <0x0400>;
				roi_control_bit = <0>;
				roi_control_addr = <0x040D>;
				roi_supported = <1>;
				glove_switch_bit = <0>;
				glove_switch_addr = <0x001D>;
				holster_switch_bit = <1>;
				holster_switch_addr = <0x001D>;
				raw_data_limit = "3405", "1225", "25", "-25", "1280", "-1280", "1280", "-1280";
				capacitance_test_config = <1>;
				report_rate_test = <0>;
				ic_type = <3>;
				raw_test_type = <1>;
				rawdata_arrange_type = <2>;
				noise_state_reg = <0x0108>;
				ic_status_reg = <0x0006>;
				touch_switch_flag = <1>;
				touch_switch_reg = <0x000c>;
				touch_switch_hold_off_reg = <0x0010>;
				adv_width = "100";
				compatible = "synaptics-VCTO24080";
			};
			VCTO24081 {
				producer = "jdi";
				roi_data_addr = <0x0400>;
				roi_control_bit = <0>;
				roi_control_addr = <0x040D>;
				roi_supported = <1>;
				glove_switch_bit = <0>;
				glove_switch_addr = <0x001D>;
				holster_switch_bit = <1>;
				holster_switch_addr = <0x001D>;
				raw_data_limit = "3405", "1225", "25", "-25", "1280", "-1280", "1280", "-1280";
				capacitance_test_config = <1>;
				report_rate_test = <0>;
				ic_type = <3>;
				raw_test_type = <1>;
				rawdata_arrange_type = <2>;
				noise_state_reg = <0x0108>;
				ic_status_reg = <0x0006>;
				touch_switch_flag = <1>;
				touch_switch_reg = <0x000c>;
				touch_switch_hold_off_reg = <0x0010>;
				adv_width = "100";
				compatible = "synaptics-VCTO24081";
			};
			VCTO21160 {
				roi_data_addr = <0x0400>;
				roi_control_bit = <0>;
				roi_control_addr = <0x0412>;
				roi_supported = <1>;
				glove_switch_bit = <5>;
				glove_switch_addr = <0x001A>;
				holster_switch_bit = <1>;
				holster_switch_addr = <0x001C>;
				ic_type = <4>;
				raw_test_type = <1>;
				producer = "sharp";
				raw_data_limit = "3000", "1200", "25", "-25", "1135", "-1135", "1135", "-1135";
				report_rate_test = <0>;
				rawdata_arrange_type = <1>;
				noise_state_reg = <0x0108>;
				ic_status_reg = <0x0004>;
				capacitance_test_config = <1>;
				touch_switch_flag = <1>;
				touch_switch_reg = <0x000c>;
				touch_switch_hold_off_reg = <0x0010>;
				adv_width = "100";
				compatible = "synaptics-VCTO21160";
			};

			VCTO21161 {
				roi_data_addr = <0x0400>;
				roi_control_bit = <0>;
				roi_control_addr = <0x0412>;
				roi_supported = <1>;
				glove_switch_bit = <5>;
				glove_switch_addr = <0x001A>;
				holster_switch_bit = <1>;
				holster_switch_addr = <0x001C>;
				ic_type = <4>;
				raw_test_type = <1>;
				producer = "sharp";
				raw_data_limit = "3000", "1200", "25", "-25", "1135", "-1135", "1135", "-1135";
				report_rate_test = <0>;
				rawdata_arrange_type = <1>;
				noise_state_reg = <0x0108>;
				ic_status_reg = <0x0004>;
				capacitance_test_config = <1>;
				touch_switch_flag = <1>;
				touch_switch_reg = <0x000c>;
				touch_switch_hold_off_reg = <0x0010>;
				adv_width = "100";
				compatible = "synaptics-VCTO21161";
			};

			VCTO21110 {
				roi_data_addr = <0x0400>;
				roi_control_bit = <0>;
				roi_control_addr = <0x0412>;
				roi_supported = <1>;
				glove_switch_bit = <5>;
				glove_switch_addr = <0x001A>;
				holster_switch_bit = <1>;
				holster_switch_addr = <0x001C>;
				ic_type = <4>;
				raw_test_type = <1>;
				producer = "tianma";
				raw_data_limit = "5000", "0", "35", "-35", "700", "-700", "700", "-700";
				report_rate_test = <0>;
				rawdata_arrange_type = <1>;
				noise_state_reg = <0x0108>;
				ic_status_reg = <0x0004>;
				capacitance_test_config = <1>;
				touch_switch_flag = <1>;
				touch_switch_reg = <0x000c>;
				touch_switch_hold_off_reg = <0x0010>;
				adv_width = "100";
				compatible = "synaptics-VCTO21110";
			};
		};
		novatek: touchscreen@01 {
			compatible = "novatek";
			ic_type = <0>;
			algo_id = <1>;
			irq_config = <2>;
			slave_address = <0x01>;
			raw_data_limit = "4600",
					"2300",
					"20",
					"-20",
					"390",
					"-390",
					"390",
					"-390";
			rawdata_get_timeout = <10>;
			y_max_mt = <1920>;
			x_max_mt = <1080>;
			y_max = <1920>;
			x_max = <1080>;
			novatek-io-supply = <&ldo4>;
			novatek-vdd-supply = <&ldo17>;
			pinctrl-1 = <&gpio065_cfg_idle>;
			pinctrl-0 = <&gpio065_cfg_func>;
			pinctrl-names = "default", "idle";
			attn_gpio = <&gpio26 4 0>;
			reset_gpio = <&gpio8 1 0>;
			projectid_len = <9>;
			ghost_detect_support = <1>;
			/* for avert misoper algo */
			feature_all = <1>;
			feature_resend_point = <1>;
			feature_orit_support = <1>;
			feature_reback_bt = <1>;
			unite_cap_test_interface =<1>;
			report_rate_test =<0>;
			lcd_width = <1080>;
			lcd_height = <1920>;
			click_time_limit = <180>;
			click_time_bt = <200>;
			edge_position = <30>;
			edge_postion_secondline = <50>;
			bt_edge_x = <80>;
			bt_edge_y = <700>;
			move_limit_x = <36>;
			move_limit_y = <36>;
			move_limit_x_t = <36>;
			move_limit_y_t = <36>;
			move_limit_x_bt = <60>;
			move_limit_y_bt = <60>;
			edge_y_confirm_t = <24>;
			edge_y_dubious_t = <16>;
			edge_y_avg_bt = <3>;
			edge_xy_down_bt = <8>;
			edge_xy_confirm_t = <36>;
			max_points_bak_num = <15>;
			/* for avert misoper algo in driver */
			drv_stop_width = <10>;
			sensor_x_width = <4>;
			sensor_y_width = <4>;

			VCTO33100 {
				roi_data_addr = <0x0418>;
				roi_control_bit = <0>;
				roi_control_addr = <0x041B>;
				roi_supported = <1>;
				glove_switch_bit = <0>;
				glove_switch_addr = <0x001F>;
				holster_switch_bit = <0>;
				holster_switch_addr = <0x0419>;
				ic_type = <0>;
				producer = "lg";
				raw_data_limit = "5000", "0", "5000", "-5000", "5000", "-5000", "5000", "-5000";
				report_rate_test = <0>;
				touch_switch_flag = <1>;
				compatible = "VCTO33100";
			};
		};
	};

	/* audio device beg */
	codec_controller: codec_controller@e82b9000 {
		gpios = <&gpio26 1 0>, <&gpio5 5 0>; /* GPIO_209 GPIO_045 */
		gpio_reset = <45>; /* GPIO_5_5*/
		gpio_codec_ssi = <201>;
		hisilicon,bus-sel = "ssi";
		gpio_codec_ssi_func = <1>;
		gpio_ssi_mux = <16>; /* Chicago FPGA only */
		pm_runtime_support;
		status = "ok";

		hi64xx_irq: hi64xx_irq@0 {
			status = "ok";

			hi6402_codec: hi6402_codec@0{
				hisilicon,mic_num = <2>;
				status = "disabled";
			};

			hi6403_codec: hi6403_codec@0{
				hisilicon,mic_num = <2>;
				use_stereo_smartpa = <0>;
				status = "disabled";
			};

			hi6403es_codec: hi6403es_codec@0{
				hisilicon,mic_num = <2>;
				use_stereo_smartpa = <0>;
				status = "ok";
			};

			gpio29: gpio@0{
				status = "disabled";
			};

			gpio30: gpio@1{
				status = "disabled";
			};

			gpio31: gpio@2{
				status = "disabled";
			};

			gpio32: gpio@3{
				status = "disabled";
			};

			pmx4: hi6402_pinctrl {
				status = "disabled";
			};
		};
	};

	codecssi@0xe82b9000 {
		/* ssi pinctrl */
		pinctrl-names = "default", "idle";
		pinctrl-0 = <&gpio201_cfg_func &gpio201_pmx_func>;
		pinctrl-1 = <&gpio201_cfg_idle &gpio201_pmx_idle>;
		status = "disabled";
	};

	sound {
		compatible = "hisilicon,hi3xxx-hi6403es";
		status = "ok";
	};

	hi6210_hifi {
		compatible = "hi6210-hifi";
		status = "ok";
	};

	asp_irq: asp_irq@E804E000{
		compatible = "hisilicon,hi3630-asp-irq";
		reg = <0x0 0xe804e000 0x0 0xa000>;
		#interrupt-cells = <0x2>;
		asp-irq-supply = <&asp>;
		interrupt-controller;
		interrupts = <0x0 0x88 0x4>;
		interrupt-names = "asp_irq";

		asp_common@0 {
			compatible = "hisilicon,hi3630-asp-common";
		};

		asp_srcup_normal@0 {
			compatible = "hisilicon,hi3630-srcup-normal";
			asp-srcup-normal-supply = <&asp>;
			interrupt-parent = <&asp_irq>;
			interrupts = <0x1 0x0>;
			interrupt-names = "asp_srcup_normal";
		};

		asp_srcup_dsp@0 {
			compatible = "hisilicon,hi3630-srcup-dsp";
		};

		asp_srcdown@0 {
			compatible = "hisilicon,hi3630-srcdown";
			interrupt-parent = <&asp_irq>;
		};

		asp_hdmi@0 {
			compatible = "hisilicon,hi3630-pcm-hdmi";
			interrupt-parent = <&asp_irq>;
			interrupts = <0x0 0x0>;
			interrupt-names = "asp_irq_hdmi";
		};
	};

	slimbusmisc@0xe8050000 {
		compatible = "candance,slimbus";
		reg = <0x0 0xe8050000 0x0 0xb00>,
			<0x0 0xe804e000 0x0 0xa000>,
			<0x0 0xfff0a000 0x0 0x1000>;
		interrupts = <0x0 0x96 0x4>;
		interrupt-names = "asp_irq_slimbus";
		slimbus-reg-supply = <&asp>;
		pinctrl-names = "default", "idle";
		pinctrl-0 = <&gpio189_pmx_func
				&gpio190_pmx_func
				&gpio189_cfg_func
				&gpio190_cfg_func>;
		pinctrl-1 = <&gpio189_pmx_idle
				&gpio190_pmx_idle
				&gpio189_cfg_idle
				&gpio190_cfg_idle>;
		slimbus-ssi-sel = "slimbus";
		asp_power_state_offset = <0x06c>;
		platform-type   = "ASIC";
		codec-type = "slimbus-6403cs";
		clk_asp_subsys = <533000>;
		slimbus_dynamic_freq = "true";
		pm_runtime_support;
		status = "ok";
	};

	slimbus_dai@0 {
		compatible = "hisilicon,slimbus-dai";
		status = "ok";
	};
        slimbus_test@0 {
               compatible = "hisilicon,slimbus_test";
               status = "ok";
        };
	sio@E804F000 {
		compatible = "hisilicon,hi3630-sio";
		reg = <0x0 0xE804F000 0x0 0x400>;
		sio-audio-supply = <&asp>;
		/* wbd
		pinctrl-names = "default", "idle";
		pinctrl-0 = <&gpio183_pmx_func
				    &gpio184_pmx_func
				    &gpio185_pmx_func
				    &gpio186_pmx_func
				    &gpio183_cfg_func
				    &gpio184_cfg_func
				    &gpio185_cfg_func
				     &gpio186_cfg_func>;
		pinctrl-1 = <&gpio183_pmx_idle
				    &gpio184_pmx_idle
				    &gpio185_pmx_idle
				    &gpio186_pmx_idle
				    &gpio183_cfg_idle
				    &gpio184_cfg_idle
				    &gpio185_cfg_idle
				    &gpio186_cfg_idle>;
		*/
		status = "ok";
	};

	sio@E804F400 {
		compatible = "hisilicon,hi3630-sio";
		reg = <0x0 0xE804F400 0x0 0x400>;
		sio-voice-supply = <&asp>;
		/* wbd
		pinctrl-names = "default", "idle";
		pinctrl-0 = <&gpio043_pmx_func
				     &gpio044_pmx_func
				     &gpio045_pmx_func
				     &gpio046_pmx_func
				     &gpio043_cfg_func
				     &gpio044_cfg_func
				     &gpio045_cfg_func
				     &gpio046_cfg_func>;
			pinctrl-1 = <&gpio043_pmx_idle
				     &gpio044_pmx_idle
				     &gpio045_pmx_idle
				     &gpio046_pmx_idle
				     &gpio043_cfg_idle
				     &gpio044_cfg_idle
				     &gpio045_cfg_idle
				     &gpio046_cfg_idle>;
		*/
		status = "ok";
	};

	sio@E804F800 {
		compatible = "hisilicon,hi3630-sio";
		reg = <0x0 0xE804F800 0x0 0x400>;
		status = "disabled";
	};

	sio@E804FC00 {
		compatible = "hisilicon,hi3630-sio";
		reg = <0x0 0xE804FC00 0x0 0x400>;
		status = "disabled";
	};

	asp_dmac@E804B000 {
		compatible = "hisilicon,hi3xxx-pcm-asp-dma";
		reg = <0x0 0xe804b000 0x0 0x1000>;
		asp-dmac-supply = <&asp>;
		status = "ok";
	};

	st_asp_dmac@E804B000 {
		compatible = "hisilicon,soundtrigger_dma_drv";
		reg = <0x0 0xe804b000 0x0 0x1000>;
		asp-dmac-supply = <&asp>;
		status = "ok";
	};

	hi64xx_asp_dmac@E804B000 {
		compatible = "hisilicon,hi64xx-asp-dma";
		reg = <0x0 0xe804b000 0x0 0x1000>;
		asp-dmac-supply = <&asp>;
		interrupts = <0 216 4>;
		interrupt-names = "asp_dma_irq";
		status = "ok";
	};

        hifidsp {
                compatible = "hisilicon,k3hifidsp";
                status = "ok";
        };

	hifi_voice_proxy {
		status = "ok";

		voice_proxy_volte {
			status = "ok";
		};

		voice_proxy_vowifi {
			status = "ok";
		};
	};

	sochifi_watchdog {
		compatible = "hisilicon,sochifi-watchdog";
		interrupts = <0 213 4>;
		status = "ok";
	};

	deviceboxID: deviceboxID@0 {
		check_mode = "gpio";
		box_num = <1>;
		enable_boxID = <1 0 0 0>;
		gpio_num = <1 0 0 0>;
		gpio_speakerID = <&gpio5 2 0>;
		speaker_map = <1 2>;/*1 means AAC, 2 means GEER&GETTOP*/

		pinctrl-names = "default", "idle";
		pinctrl-0 = <&gpio042_pmx_func &gpio042_cfg_func>;
		pinctrl-1 = <&gpio042_pmx_idle &gpio042_cfg_idle>;
		deviceboxID_limit = <500>;
		status = "ok";
	};

	audio_hw_config {
		product_name = "VICTORIA";
		multi_mic_enable = "false";
		vqm_enable = "true";
		spk_pa_name = "max98925";
		cust_name = "audio_custom";
		soc_name = "hi363x";
		codec_name = "hi6403";
		codec_dsp_algo = "maxim|mad";
		modem_sio_master = "false";
		ear_pa_name = "none";
		status = "ok";
		hardware_info {
			mic_num = "2";
			mic_type = "0003";/*0001 deputy mic   0002 main mic   0004 deputy mic2   0008 main mic2*/
			status = "ok";
		};
		audio_capability {
			bwe_ui_support = "true";
			bwe_support = "true";
			swb_support = "true";
			wnr_support = "true";
			nv_evs_support = "true";
			lvm_support = "true";
			dhf_support = "false";
			voice_anc_support = "false";
			dual_smartpa_support = "false";
			spk_rcv_stereo_support = "false";
			earphone_multi_eq_support = "true";
			vdr_ui_support = "false";
			asr_vibrate_support = "true";
			visualizer_support = "true";
			visualizer_frame = "Medium";
			/*
				sound trigger feature.
				false: this product doesn't support soundtrigger feature.
				2.0: this product supports the twice wakeup feature.
			*/
			soundtrigger_version = "2.0";
		};
	};

	hw_soundtrigger_event: hw_soundtrigger_event{
		status = "ok";
	};
	/* audio device end */

	/* UFS */
	ufs: ufs@FF3b0000 {
		ufs-kirin-use-rate-B;
		ufs-kirin-broken-fastauto;
		/*ufs-kirin-use-one-line;*/
		ufs-kirin-use-HS-GEAR3;
		/*ufs-kirin-use-HS-GEAR2;*/
		/*ufs-kirin-use-HS-GEAR1;*/
		ufs-kirin-unipro-termination;
		/*ufs-kirin-unipro-scrambing;*/
		/*ufs-kirin-use-auto-H8*/
		/*ufs-kirin-broken-clk-gate-pypass*/
		ufs-0db-equalizer-product-names = "THGBF7G8K4LBATRC";
		ufs-refclk-drive-4ma-product-names = "hC8aL1";
		ufs-force-link-llane-product-names = "hC8aL1";
		ufs-ber-start-calc-value = <10>;
	};

	/* eMMC0 */
	sdhci0: sdhci@FF3FB000 {
		clk-ahb = <115000000>;
		clk-xin = <192000000>;
		vmmc-supply = <&ldo15>;
		caps2-mmc-hs400-1_8v;/*caps2-mmc-hs400-1_8v, caps2-mmc-hs200-1_8v, caps2-mmc-ddr50-1_8v*/
		/*caps2-mmc-packed-command;*/
		keep-power-in-suspend;
		/*caps2-mmc-poweroff-notify;*/
		/*caps2-mmc-enhanced_strobe-ctrl;*/
		/*caps2-mmc-cache_flush_barrier-ctrl;*/
		caps2-mmc-bkops_auto-ctrl;
		caps2-mmc-cmd-queue;
		status = "disabled";
	};

	/* SD */
	dwmmc1: dwmmc1@FF37F000 {
		vmmc-supply = <&ldo16>;
		vqmmc-supply = <&ldo9>;
		cd-vol = <1>;
		cd-gpio = <&gpio25 3 0>;
		shared-irq = <1>;
		status = "ok";
	};

	/* wifi */
	dwmmc2: dwmmc2@FF3FF000 {
		sdio_support_uhs;
		caps2-support-wifi;
		status = "ok";
	};

	hisi_usb@ff200000 {
		usbldo10-supply = <&ldo10>;
		eye_diagram_param = <0x1c466e3>;
		eye_diagram_host_param = <0x2cdc6e7>;

		dwc3@ff100000 {
			maximum-speed = "high-speed";
		};
	};

	sensorhub_status{
		compatible = "huawei,sensorhub_status";
		status= "ok";
	};

	sensorhub_nmi{
		compatible = "huawei,sensorhub_nmi";
		nmi_reg=<0x588>;
	};
	gps_power: gps_power{
		status = "ok";
		huawei,gps_en = <&gpio4 4 0>;
		huawei,gps_hostwake = <&gpio26 3 0>;
		pinctrl-0 = <&gpio012_pmx_func &gpio012_cfg_func>;
		pinctrl-1 = <&gpio012_pmx_idle &gpio012_cfg_idle>;
		huawei,gps_refclk = <12>;
		huawei,mcu_req = <&gpio9 7 0>;
		huawei,mcu_req_rsp = <&gpio10 7 0>;
		broadcom_config,ic_type="bcm4774";
		broadcom_config,tty_port="ttyAMA3";
		factest_timeout="9";
	};
	hisi_flp:flp {
	hisi,flp_switch = "off";    /* on/off */
    };
	sensorhub{
		#address-cells=<1>;
		#size-cells=<0>;
		als_sensor:light{
			als1{
				compatible="huawei,rohm_bh1745";
				reg=<0x38>;
				chip_id_value=<0xE0>;
				file_id=<38>;
				poll_interval=<350>;
				gpio_int1=<&gpio26 6 0>;
				als_phone_type = <23>;
				als_phone_version = <10>;
				als_extend_data = <0 0 0 0 0 0 0 0 0 0 0 0>;
				status = "ok";
				sensorlist_name="light-bh1745";
				vendor="rohm";
			};
			als2{
				compatible="huawei,avago_apds9251";
				bus_number = <0x0>;
				reg=<0x52>;
				chip_id_register = <0x06>;
				chip_id_value = <0xB2 0xB5>;
				file_id = <41>;
				sensor_list_info_id = <0x3>;
				sensor_type = "als";
				poll_interval = <120>;
				threshold_value = <0x1>;
				GA1 = <0x1046>;
				GA2 = <0xf3c>;
				GA3 = <0x1194>;
				tp_color = <0x0>;
				again = <0x1>;
				gpio_int1 = <0x38 0x6 0x0>;
				atime = <0xdb>;
				init_time = <0x96>;
				status = "ok";
				als_phone_type = <23>;
				als_phone_version = <12>;
				als_extend_data = <0x0 0x0 0x0 0x0 0x0 0x0 0x0 0x0 0x0 0x0 0x0 0x0>;
				sensorlist_name="als-apds9251";
				vendor="avago";
			};
		};

		ps_sensor:proximity{
			ps1{
				compatible="huawei,txc-pa224";
				reg=<0x1e>;
				chip_id_register=<0x7F>;
				chip_id_value=<0x11>;
				file_id=<39>;
				min_proximity_value=<220>;
				pwindows_value=<22>;
				pwave_value=<10>;
				threshold_value=<25>;
				gpio_int1=<&gpio27 1 0>;
				poll_interval = <30>;
				ps_oily_threshold = <3>;
				status = "ok";
				sensorlist_name="proximity-pa224";
				vendor="txc";
				fifoReservedEventCount=<0>;
				fifoMaxEventCount=<0>;
				maxDelay=<200000>;
			};
			ps2{
				compatible="huawei,avago-apds9110";
				bus_number=<0>;
				reg=<0x53>;
				chip_id_register=<0x6>;
				chip_id_value=<0xB1>;
				file_id=<49>;
				sensor_list_info_id=<0x4>;
				sensor_type="ps";
				//sensor-vdd-supply = <&ldo24>;
				tp_color =<0>;
				min_proximity_value=<220>;
				pwindows_value=<25>;
				pwave_value=<17>;
				threshold_value=<18>;
				ps_pulse_count=<5>;
				persistent=<0x33>;
				rdata_under_sun=<5500>;
				gpio_int1=<&gpio25 6 0>;
				ptime=<0xFF>;
				p_on = <1>;
				poll_interval = <80>;
				init_time = <50>;
				sensorlist_name="proximity-apds9110";
				vendor="avago";
				fifoReservedEventCount=<0>;
				fifoMaxEventCount=<0>;
				maxDelay=<200000>;
				status = "ok";
			};
		};

		acc_sensor:gsensor{
			acc1{
				compatible ="huawei,st-lsm6dsm";
				bus_number =<0>;
				reg =<0x6a>;
				chip_id_register =<0x0f>;
				chip_id_value =<0x6a>;
				file_id =<34>;
				sensor_list_info_id =<0>;
				sensor_type ="acc";
				axis_map_x =<0>;
				axis_map_y =<1>;
				axis_map_z =<2>;
				negate_x =<0>;
				negate_y =<1>;
				negate_z =<1>;
				offset_x =<0>;
				offset_y =<0>;
				offset_z =<0>;
				sensitivity_x =<1>;
				sensitivity_y =<1>;
				sensitivity_z =<1>;
				poll_interval =<10>;
				gpio_int1 =<&gpio26 0 0>;
				gpio_int2=<&gpio24 1 0>;
				gpio_int2_sh=<227>;
				calibrate_style =<0>;
				sensorlist_name="accelerometer-lsm6dsm";
				vendor="st";
				maxRange=<8>;
				power=<230>;
				minDelay=<2000>;
				fifoReservedEventCount=<0>;
				fifoMaxEventCount=<0>;
				maxDelay=<200000>;
				status = "ok";
			};
			acc2{
				compatible ="huawei,invensense-icm20690";
				bus_number =<0>;
				reg =<0x68>;
				chip_id_register =<0x75>;
				chip_id_value =<0x20>;
				file_id =<53>;
				sensor_list_info_id =<0>;
				sensor_type ="acc";
				axis_map_x =<0>;
				axis_map_y =<1>;
				axis_map_z =<2>;
				negate_x =<0>;
				negate_y =<1>;
				negate_z =<1>;
				offset_x =<0>;
				offset_y =<0>;
				offset_z =<0>;
				sensitivity_x =<1>;
				sensitivity_y =<1>;
				sensitivity_z =<1>;
				poll_interval =<10>;
				gpio_int1 =<&gpio26 0 0>;
				gpio_int2=<&gpio24 1 0>;
				gpio_int2_sh=<227>;
				calibrate_style =<0>;
				sensorlist_name="accelerometer-icm20690";
				vendor="invensense";
				maxRange=<8>;
				power=<230>;
				minDelay=<2000>;
				fifoReservedEventCount=<0>;
				fifoMaxEventCount=<0>;
				maxDelay=<200000>;
				status = "ok";
			};
		};

		gyro_sensor:gyroscope{
			gyro1{
				compatible ="huawei,st-lsm6dsm";
				bus_number =<0>;
				reg =<0x6a>;
				chip_id_register =<0x0f>;
				chip_id_value =<0x6a>;
				file_id =<36>;
				sensor_list_info_id =<5>;
				sensor_type ="gyro";
				axis_map_x =<0>;
				axis_map_y =<1>;
				axis_map_z =<2>;
				negate_x =<0>;
				negate_y =<1>;
				negate_z =<1>;
				poll_interval =<10>;
				gpio_int1 =<&gpio26 2 0>;
				gpio_int2=<&gpio24 1 0>;
				gpio_int2_sh=<227>;
				sensorlist_name="gyroscope-lsm6dsm";
				vendor="st";
				minDelay=<2000>;
				maxDelay=<200000>;
				status = "ok";
			};
			gyro2{
				compatible ="huawei,inv-icm20690";
				bus_number =<0>;
				reg =<0x68>;
				chip_id_register =<0x75>;
				chip_id_value =<0x20>;
				file_id =<54>;
				sensor_list_info_id =<5>;
				sensor_type ="gyro";
				axis_map_x =<0>;
				axis_map_y =<1>;
				axis_map_z =<2>;
				negate_x =<0>;
				negate_y =<1>;
				negate_z =<1>;
				poll_interval =<10>;
				gpio_int1 =<&gpio26 2 0>;
				gpio_int2=<&gpio24 1 0>;
				gpio_int2_sh=<227>;
				sensorlist_name="gyroscope-icm20690";
				vendor="invensense";
				minDelay=<2000>;
				maxDelay=<200000>;
				status = "ok";
			};
		};
		mag_sensor:compass{
			mag1{
				compatible="huawei,akm-akm09911";
				bus_number=<0>;
				reg=<0x0D>;
				chip_id_register=<0x00>;
				chip_id_value=<0x48>;
				file_id=<37>;
				sensor_list_info_id=<1>;
				sensor_type="mag";
				/*sensor-vdd-supply = <&ldo24>;*/
				outbit=<0>;
				softfilter = <2>;
				calibrate_method=<2>;
				axis_map_x=<0>;
				axis_map_y=<1>;
				axis_map_z=<2>;
				negate_x=<0>;
				negate_y=<0>;
				negate_z=<0>;
				poll_interval=<10>;
				charger_trigger=<1>;
				gpio_int1=<&gpio0 0 0>;
				gpio_reset=<&gpio0 0 0>;
				softiron_parameter = <233 40 254 2 13 0 254 2 19 44 240 254 13 0 240 254 81 47 0 0 0 0 0 0 0 0 0>;
				sensorlist_name="mag-akm09911";
				vendor="akm";
				minDelay=<10000>;
				fifoReservedEventCount=<0>;
				fifoMaxEventCount=<0>;
				status = "ok";
			};
			mag2{
				compatible="huawei,yamaha-yas537";
				bus_number=<0>;
				reg=<0x2E>;
				chip_id_register=<0x80>;
				chip_id_value=<0x07>;
				file_id=<66>;
				sensor_list_info_id=<1>;
				sensor_type="mag";
				/*sensor-vdd-supply = <&ldo24>;*/
				outbit=<0>;
				softfilter = <2>;
				calibrate_method=<2>;
				axis_map_x=<0>;
				axis_map_y=<1>;
				axis_map_z=<2>;
				negate_x=<0>;
				negate_y=<0>;
				negate_z=<0>;
				poll_interval=<10>;
				charger_trigger=<1>;
				gpio_int1=<&gpio0 0 0>;
				gpio_reset=<&gpio0 0 0>;
				softiron_parameter = <16 39 0 0 0 0 0 0 16 39 0 0 0 0 0 0 16 39 0 0 0 0 0 0 0 0 0>;
				sensorlist_name="mag-yas537";
				vendor="yamaha";
				minDelay=<10000>;
				fifoReservedEventCount=<0>;
				fifoMaxEventCount=<0>;
				status = "ok";
			};
		};
		airpress_sensor:airpress{
			airpress1{
				compatible="huawei,st_lps22bh";
				bus_number=<0>;
				reg=<0x5d>;
				chip_id_register=<0x0F>;
				chip_id_value=<0xB1>;
				file_id=<48>;
				sensor_list_info_id=<0x9>;
				sensor_type="airpress";
				poll_interval = <500>;
				sensorlist_name="airpress-lps22bh";
				vendor="st";
				fifoReservedEventCount=<0>;
				fifoMaxEventCount=<0>;
				status = "disabled";
			};
		};
		fingerprint_sensor:fingerprint{
			finger1{
				compatible="fpc,fpc1021";
				bus_type=<1>;
				bus_number=<2>;
				reg=<0x0>;
				chip_id_register=<0xFC>;
				chip_id_value=<0x8206>;
				file_id=<22>;
				sensor_list_info_id = <0x12>;
				sensor_type ="fingerprint";
				poll_interval = <500>;
				gpio_int = <207>;
				gpio_int_sh = <236>;
				gpio_reset = <149>;
				gpio_cs = <218>;
				status = "ok";
			};
		};
		gps_i2c_sensor:gps_4774_i2c{
			gps_4774_i2c{
				compatible="huawei,gps_4774_i2c";
				bus_number=<0>;
				reg=<0x6e>;
				chip_id_register=<0x91>;
				chip_id_value=<0x00>;
				file_id=<47>;
				sensor_list_info_id=<0x23>;
				sensor_type="gps_4774_i2c";
				gpio1_gps_cmd_ap = <200>;
				gpio1_gps_cmd_sh = <230>;
				gpio2_gps_ready_ap = <210>;
				gpio2_gps_ready_sh = <239>;
				gpio3_wakeup_gps_ap = <220>;
				gpio3_wakeup_gps_sh = <249>;
				status = "ok";
			};
		};
		magn_bracket_sensor:magn_bracket{
			magn_bracket{
				compatible="huawei,magn_bracket";
				sensor_type="hw_magn_bracket";
				file_id=<21>;
				sensor_list_info_id = <23>;
				mag_axis_change = <0x82 0x9c4 0xfa 0x1388 0xfffff254 0xffffff38>;
				sensorlist_name="magn_bracket";
				vendor="hw";
				status = "ok";
			};
		};
	};

	sensorhub_ext_config:sensorhub_ex{
		compatible = "huawei,sensorhub";
		akm_need_current = "no";
		invensense_exist = "no";
		isensor_version = "no";
		sensor_1v8_from_pmic = "yes";
		sensor_1v8_ldo = <1>;
		adapt_file_id = <8 9 14>;
		hifi_support = <0>;
		adapt_sensor_list_id = <2 6 7 8 11 12 13 14 15 16 17 18 21 22>;
	};

	sensorhub_io_power{
		compatible = "huawei,sensorhub_io";
		sensor-io-supply = <&ldo24>;
		need-reset = <1>;
		status="ok";
	};

	hall {
		compatible = "huawei,hall_sensor,ak8789";
		status = "ok";
		huawei,hall_0{
			huawei,single-n-pole = <&gpio24 7 0>;
			huawei,type = <0x01>;
			huawei,default-state = "on";
		};
	};
	/*
		device check : the 0 means that it donot need to check;
			the 1 means that it check at board check and running test;
			the 2 means that it check at running test
	*/
	devcheck: devcheck {
		touch_panel = <2>;
		compass = <1>;
		g_sensor = <1>;
		gyroscope = <1>;
		nfc = <1>;
		dc_dc = <1>;
		tps = <1>;
		l_sensor = <2>;
		charge = <1>;
		usb_switch = <1>;
		wifi = <1>;
		bt = <1>;
		gps = <1>;
		antenna_ctl = <0>;
		airpress = <0>;
		vibrator_lra = <1>;
		laser = <1>;
		camera_pmic = <1>;
		anc_max14744 = <1>;
		anc_ncx8293 = <1>;
		charge_loadswitch = <1>;
		max77813 = <1>;
		status = "ok";
	};

	hisi,hisi_camera {
		hisi,is_fpga = <0>;
	};

	/* Camera f2.2 */
	camera_hw_config {
		product_name = "VICTORIA";
		lens_type = "true"; /* false f1.8, true f2.2 */
	};

	huawei,hisi_isp150 {
		status = "ok";
		pinctrl-names = "default", "idle";
		hisi,is_fpga = <0>;
		pinctrl-1 = <
				&gpio027_pmx_idle // ISP_SCL0
				&gpio028_pmx_idle // ISP_SDA0
				&gpio029_pmx_idle // ISP_SCL1
				&gpio030_pmx_idle // ISP_SDA1
				&gpio031_pmx_idle // ISP_SDA2
				&gpio032_pmx_idle // ISP_SDA2
				&gpio052_pmx_idle // CAM0_RST
				&gpio075_pmx_idle // CAM1_RST

				&gpio027_cfg_idle
				&gpio028_cfg_idle
				&gpio029_cfg_idle
				&gpio030_cfg_idle
				&gpio031_cfg_idle
				&gpio032_cfg_idle
				&gpio052_cfg_idle
				&gpio075_cfg_idle
				>;
		pinctrl-0 = <
				&gpio027_pmx_func // ISP_SCL0
				&gpio028_pmx_func // ISP_SDA0
				&gpio029_pmx_func // ISP_SCL1
				&gpio030_pmx_func // ISP_SDA1
				&gpio031_pmx_func // ISP_SDA2
				&gpio032_pmx_func // ISP_SDA2
				&gpio052_pmx_func // CAM0_RST
				&gpio075_pmx_func // CAM1_RST

				&gpio027_cfg_func
				&gpio028_cfg_func
				&gpio029_cfg_func
				&gpio030_cfg_func
				&gpio031_cfg_func
				&gpio032_cfg_func
				&gpio052_cfg_func
				&gpio075_cfg_func
				>;
	};

	huawei,imx286dual{
		compatible = "huawei,imx286dual_ml";
		huawei,sensor_name = "IMX286DUAL";
		huawei,sensor_index = <0>;
		huawei,is_fpga = <0>;
		huawei,pd_valid = <1>;
		huawei,reset_valid = <1>;
		huawei,vcmpd_valid = <0>;
		huawei,csi_index = <0 2>;
		huawei,i2c_index = <0 2>;
		clocks = <&clk_gate_isp_snclk0 &clk_gate_isp_snclk2>;
		clock-names = "clk_isp_snclk0", "clk_isp_snclk2";
		huawei,mclk = <24000000>;
		avdd0-supply = <&ldo19>;
		avdd1-supply = <&ldo31>;
		huawei,ldo-names = "avdd0", "avdd1";
		gpios = <&gpio6 4 0 &gpio2 5 0>;
		huawei,gpio-ctrl-types = "reset", "reset2";
		module_type = <0>;/*bit0=enable ,other bits=type*/
		status = "disabled";
	};

	huawei,imx179 {
		compatible = "huawei,imx179_ml";
		huawei,sensor_name = "IMX179_4L_FOXCONN";
		huawei,is_fpga = <0>;
		huawei,pd_valid = <1>;
		huawei,csi_index = <1>;
		huawei,i2c_index = <1>;
		huawei,reset_valid = <1>;
		clocks = <&clk_gate_isp_snclk1>;
		clock-names = "clk_isp_snclk1";
		huawei,mclk = <24000000>;

		vcm-supply = <&ldo25>;
		avdd-supply = <&ldo13>;
		dvdd-supply = <&ldo32>;
		huawei,ldo-names = "vcm", "avdd", "dvdd";

		gpios = <&gpio9 3 0>;
		huawei,gpio-ctrl-types = "reset";
		status = "disabled";
	};

	huawei,ov8865 {
		compatible = "huawei,ov8865_ml";
		huawei,sensor_name = "OV8865";
		huawei,is_fpga = <0>;
		huawei,pd_valid = <1>;
		huawei,sensor_index = <1>;
		huawei,csi_index = <1>;
		huawei,i2c_index = <1>;
		huawei,reset_valid = <1>;
		clock-names = "clk_isp_snclk1";
		clocks = <&clk_gate_isp_snclk1>;
		huawei,mclk = <24000000>;

		huawei,vcmpd_valid = <0>;
		vcm-supply = <&ldo25>;
		avdd-supply = <&ldo13>;
		dvdd-supply = <&ldo32>;
		huawei,ldo-names = "vcm", "avdd", "dvdd";

		gpios = <&gpio9 3 0>;
		huawei,gpio-ctrl-types = "reset";
		status = "disabled";
	};
	huawei,imx219 {
		compatible = "huawei,imx219_vic";
		huawei,sensor_name = "IMX219_VIC_LITEON";
		huawei,is_fpga = <0>;
		huawei,pd_valid = <1>;
		huawei,sensor_index = <1>;
		huawei,csi_index = <1>;
		huawei,i2c_index = <1>;
		huawei,reset_valid = <1>;
		clock-names = "clk_isp_snclk1";
		clocks = <&clk_gate_isp_snclk1>;
		huawei,mclk = <24000000>;
		huawei,vcmpd_valid = <0>;
		vcm-supply = <&ldo25>;
		avdd-supply = <&ldo13>;
		dvdd-supply = <&ldo32>;
		huawei,ldo-names = "vcm", "avdd", "dvdd";
		gpios = <&gpio9 3 0>;
		huawei,gpio-ctrl-types = "reset";
		status = "ok";
	};

	huawei,imx319 {
		compatible = "huawei,imx319";
		huawei,sensor_name = "IMX319_SUNNY";
		huawei,is_fpga = <0>;
		huawei,pd_valid = <1>;
		huawei,sensor_index = <1>;
		huawei,csi_index = <1>;
		huawei,i2c_index = <1>;
		huawei,reset_valid = <1>;
		clock-names = "clk_isp_snclk1";
		clocks = <&clk_gate_isp_snclk1>;
		huawei,mclk = <24000000>;

		huawei,vcmpd_valid = <0>;
		vcm-supply = <&ldo25>;
		avdd-supply = <&ldo13>;
		dvdd-supply = <&ldo32>;
		huawei,ldo-names = "vcm", "avdd", "dvdd";

		gpios = <&gpio9 3 0>;
		huawei,gpio-ctrl-types = "reset";
		status = "ok";
	};

	huawei,imx286hybird{
		compatible = "huawei,imx286hybird";
		huawei,sensor_name = "IMX286HYBIRD";
		huawei,sensor_index = <0>;
		huawei,is_fpga = <0>;
		huawei,pd_valid = <1>;
		huawei,reset_valid = <1>;
		huawei,vcmpd_valid = <0>;
		huawei,csi_index = <0 2>;
		huawei,i2c_index = <0 2>;
		clocks = <&clk_gate_isp_snclk0 &clk_gate_isp_snclk2>;
		clock-names = "clk_isp_snclk0", "clk_isp_snclk2";
		huawei,mclk = <24000000>;
		avdd0-supply = <&ldo19>;
		avdd1-supply = <&ldo31>;
		huawei,ldo-names = "avdd0", "avdd1";
		gpios = <&gpio6 4 0 &gpio2 5 0>;
		huawei,gpio-ctrl-types = "reset", "reset2";
		module_type = <0>;/*bit0=enable ,other bits=type*/
		status = "disabled";
	};

	huawei,imx386hybird{
		compatible = "huawei,imx386hybird";
		huawei,sensor_name = "IMX386HYBIRD";
		huawei,sensor_index = <0>;
		huawei,is_fpga = <0>;
		huawei,pd_valid = <1>;
		huawei,reset_valid = <1>;
		huawei,vcmpd_valid = <0>;
		huawei,csi_index = <0 2>;
		huawei,i2c_index = <0 2>;
		clocks = <&clk_gate_isp_snclk0 &clk_gate_isp_snclk2>;
		clock-names = "clk_isp_snclk0", "clk_isp_snclk2";
		huawei,mclk = <24000000>;
		avdd0-supply = <&ldo19>;
		avdd1-supply = <&ldo31>;
		huawei,ldo-names = "avdd0", "avdd1";
		gpios = <&gpio6 4 0 &gpio2 5 0>;
		huawei,gpio-ctrl-types = "reset", "reset2";
		module_type = <0>;/*bit0=enable ,other bits=type*/
		status = "ok";
	};

	huawei,imx486hybird{
		compatible = "huawei,imx486hybird";
		huawei,sensor_name = "IMX486HYBIRD";
		huawei,sensor_index = <0>;
		huawei,is_fpga = <0>;
		huawei,pd_valid = <1>;
		huawei,reset_valid = <1>;
		huawei,vcmpd_valid = <0>;
		huawei,csi_index = <0 2>;
		huawei,i2c_index = <0 2>;
		clocks = <&clk_gate_isp_snclk0 &clk_gate_isp_snclk2>;
		clock-names = "clk_isp_snclk0", "clk_isp_snclk2";
		huawei,mclk = <24000000>;
		avdd0-supply = <&ldo19>;
		avdd1-supply = <&ldo31>;
		huawei,ldo-names = "avdd0", "avdd1";
		gpios = <&gpio6 4 0 &gpio2 5 0>;
		huawei,gpio-ctrl-types = "reset", "reset2";
		module_type = <0>;/*bit0=enable ,other bits=type*/
		status = "ok";
	};

	huawei,vl53l0_ml {
		compatible = "huawei,vl53l0_ml";
		huawei,laser_name = "VL53L0_ST";
		product_name = "MHA";
		huawei,i2c_idx = <2>;
		gpios = <&gpio8 4 0>;
		huawei,gpio-ctrl-types = "xshut";
		pinctrl-names = "default", "idle";
		pinctrl-0 = <&gpio068_pmx_func &gpio068_cfg_func>;
		pinctrl-1 = <&gpio068_pmx_idle &gpio068_cfg_idle>;
		status = "ok";
	};

	nfc_exist{
		status = "ok";
		nfc_exist_flag = "1";
	};

	bcm_wifi {
		compatible = "hisilicon,bcm_wifi";
		ic_type = "bcm4359";
		wifi_fw_test_name = "/vendor/firmware/fw_bcm4359_test_hw_apsta.bin";
		wifi_fw_ap_name = "/vendor/firmware/fw_bcm4359_apsta_hw.bin";
		wifi_fw_name = "/vendor/firmware/fw_bcm4359_hw.bin";
		wifi_nvram_name = "/vendor/firmware/nvram4359_hw.txt";
		clocks = <&clk_pmu32kb>;
		clock-names = "apb_pclk";
		interrupts = <0 282 4>;
		wlan-on,gpio-enable= <&gpio6 3 0>;
		wlan-irq,gpio-irq = <&gpio22 3 0>;
		wifi_supply_type = <1>;
		wifi_vccio-supply = <&ldo4>;
		status = "ok";
	};

    
    pmic: pmic@FFF34000 {
        sim0 {
            gpios = <&gpio25 3 0>;
            sim_id = <0>;
            status = "ok";
            func_sel_state = "not_use_multi_func";
            det_normal_direction = "closed";
            allocate_gpio = <0>;
            shared_det_irq = <1>;
            send_msg_to_cp = <1>;
            card_tray_style = <1>;
            hpd_interrupt_to_close_ldo = <0x22>;
            hpd_debounce_wait_time = <0x00>;
            det_debounce_wait_time = <300>;
            interrupt-parent = <&pmic>;
            interrupts = <25 0>;
            interrupt-names = "hpd0_falling";
            pmu_status1_address = <0x007>;
            pmu_ldo11_onoff_eco_address = <0x06E>;
            pmu_ldo11_vset_address = <0x06F>;
            pmu_ldo12_onoff_eco_address = <0x070>;
            pmu_ldo12_vset_address = <0x071>;
            pmu_sim_ctrl_address = <0x0DE>;
            pmu_sim_deb_ctrl_address = <0x0DF>;
            pmu_irq_mask3_address = <0x0E4>;
            pmu_irq3_address = <0x123>;
            pmu_ldo11_onoff_value = <0x02>;
            pmu_ldo11_vset_value = <0x01>;
            pmu_ldo12_onoff_value = <0x02>;
            pmu_ldo12_vset_value = <0x01>;
            send_card_out_msg_when_init = <0>;
        };

        sim1 {
            gpios = <&gpio25 3 0>;
            sim_id = <1>;
            status = "ok";
            func_sel_state = "not_use_multi_func";
            det_normal_direction = "closed";
            allocate_gpio = <0>;
            shared_det_irq = <1>;
            send_msg_to_cp = <1>;
            card_tray_style = <1>;
            hpd_interrupt_to_close_ldo = <0x22>;
            hpd_debounce_wait_time = <0x00>;
            det_debounce_wait_time = <300>;
            interrupt-parent = <&pmic>;
            interrupts = <29 0>;
            interrupt-names = "hpd1_falling";
            pmu_status1_address = <0x007>;
            pmu_ldo11_onoff_eco_address = <0x06E>;
            pmu_ldo11_vset_address = <0x06F>;
            pmu_ldo12_onoff_eco_address = <0x070>;
            pmu_ldo12_vset_address = <0x071>;
            pmu_sim_ctrl_address = <0x0DE>;
            pmu_sim_deb_ctrl_address = <0x0DF>;
            pmu_irq_mask3_address = <0x0E4>;
            pmu_irq3_address = <0x123>;
            pmu_ldo11_onoff_value = <0x02>;
            pmu_ldo11_vset_value = <0x01>;
            pmu_ldo12_onoff_value = <0x02>;
            pmu_ldo12_vset_value = <0x01>;
            send_card_out_msg_when_init = <0>;
        };
    };
    

	fingerprint {
		compatible = "fpc,fingerprint";
		spi-max-frequency = <5000000>;
		fingerprint,product = "victoria";

		fingerprint,navigation_adjust1 = <1>;
		fingerprint,navigation_adjust2 = <0>;

		fingerprint,fpc2050 = <1>;
		fingerprint,reset_gpio = <149>;
		fingerprint,irq_gpio = <207>;
		fingerprint,cs_gpio = <218>;
		fingerprint,extern_ldo_name = "CAM_LDO";
		fingerprint,extern_ldo_num = <2>;
		fingerprint,extern_vol = <3300000>;
		fingerprint,spi_num = <2>;
		fingerprint,force_storage_type = <1>;
		pinctrl-names = "default", "idle";
		pinctrl-0 = <&gpio149_pmx_func &gpio149_cfg_func>;
		pinctrl-1 = <&gpio149_pmx_idle &gpio149_cfg_idle>;
	};
};
